AUTOSAR XML (schema 4-2-2)
package /STELLANTIS/EPT/ASWCs
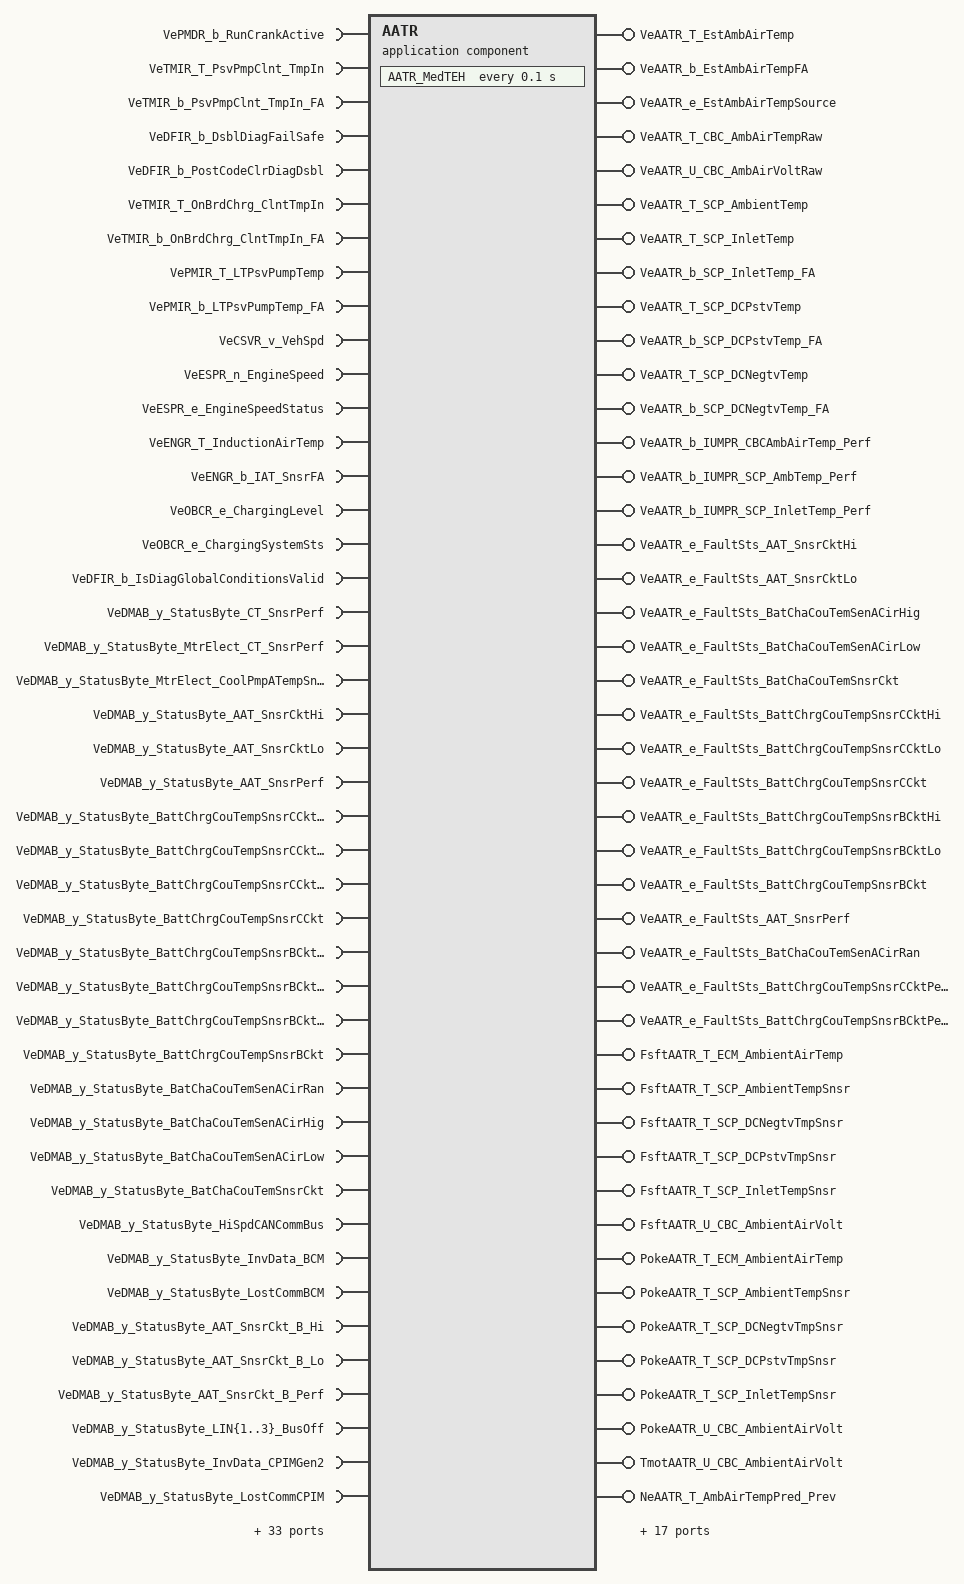
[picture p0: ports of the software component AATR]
  application sw component type AATR
    61 x require port:
      VePMDR_b_RunCrankActive: variation-point={short-label=vpVePMDR_b_RunCrankActive, sw-syscond=1}, nonqueued-receiver-com-spec{data-element=Value, init-value=0}, required-interface=VePMDR_b_RunCrankActive
      VeTMIR_T_PsvPmpClnt_TmpIn: variation-point={short-label=vpVeTMIR_T_PsvPmpClnt_TmpIn, sw-syscond=1}, nonqueued-receiver-com-spec{data-element=Value, init-value=0}, required-interface=VeTMIR_T_PsvPmpClnt_TmpIn
      VeTMIR_b_PsvPmpClnt_TmpIn_FA: variation-point={short-label=vpVeTMIR_b_PsvPmpClnt_TmpIn_FA, sw-syscond=1}, nonqueued-receiver-com-spec{data-element=Value, init-value=0}, required-interface=VeTMIR_b_PsvPmpClnt_TmpIn_FA
      VeDFIR_b_DsblDiagFailSafe: variation-point={short-label=vpVeDFIR_b_DsblDiagFailSafe, sw-syscond=1}, nonqueued-receiver-com-spec{data-element=Value, init-value=0}, required-interface=VeDFIR_b_DsblDiagFailSafe
      VeDFIR_b_PostCodeClrDiagDsbl: variation-point={short-label=vpVeDFIR_b_PostCodeClrDiagDsbl, sw-syscond=1}, nonqueued-receiver-com-spec{data-element=Value, init-value=0}, required-interface=VeDFIR_b_PostCodeClrDiagDsbl
      VeTMIR_T_OnBrdChrg_ClntTmpIn: variation-point={short-label=vpVeTMIR_T_OnBrdChrg_ClntTmpIn, sw-syscond=1}, nonqueued-receiver-com-spec{data-element=Value, init-value=0}, required-interface=VeTMIR_T_OnBrdChrg_ClntTmpIn
      VeTMIR_b_OnBrdChrg_ClntTmpIn_FA: variation-point={short-label=vpVeTMIR_b_OnBrdChrg_ClntTmpIn_FA, sw-syscond=1}, nonqueued-receiver-com-spec{data-element=Value, init-value=0}, required-interface=VeTMIR_b_OnBrdChrg_ClntTmpIn_FA
      VePMIR_T_LTPsvPumpTemp: variation-point={short-label=vpVePMIR_T_LTPsvPumpTemp, sw-syscond=1}, nonqueued-receiver-com-spec{data-element=Value, init-value=0}, required-interface=VePMIR_T_LTPsvPumpTemp
      VePMIR_b_LTPsvPumpTemp_FA: variation-point={short-label=vpVePMIR_b_LTPsvPumpTemp_FA, sw-syscond=1}, nonqueued-receiver-com-spec{data-element=Value, init-value=0}, required-interface=VePMIR_b_LTPsvPumpTemp_FA
      VeCSVR_v_VehSpd: variation-point={short-label=vpVeCSVR_v_VehSpd, sw-syscond=1}, nonqueued-receiver-com-spec{data-element=Value, init-value=0}, required-interface=VeCSVR_v_VehSpd
      VeESPR_n_EngineSpeed: variation-point={short-label=vpVeESPR_n_EngineSpeed, sw-syscond=1}, nonqueued-receiver-com-spec{data-element=Value, init-value=0}, required-interface=VeESPR_n_EngineSpeed
      VeESPR_e_EngineSpeedStatus: variation-point={short-label=vpVeESPR_e_EngineSpeedStatus, sw-syscond=1}, nonqueued-receiver-com-spec{data-element=Value, init-value=CeESPR_e_EngSpdNormal}, required-interface=VeESPR_e_EngineSpeedStatus
      VeENGR_T_InductionAirTemp: variation-point={short-label=vpVeENGR_T_InductionAirTemp, sw-syscond=1}, nonqueued-receiver-com-spec{data-element=Value, init-value=0}, required-interface=VeENGR_T_InductionAirTemp
      VeENGR_b_IAT_SnsrFA: variation-point={short-label=vpVeENGR_b_IAT_SnsrFA, sw-syscond=1}, nonqueued-receiver-com-spec{data-element=Value, init-value=0}, required-interface=VeENGR_b_IAT_SnsrFA
      VeOBCR_e_ChargingLevel: variation-point={short-label=vpVeOBCR_e_ChargingLevel, sw-syscond=1}, nonqueued-receiver-com-spec{data-element=Value, init-value=CeOBCR_e_ChargingLvlDefault}, required-interface=VeOBCR_e_ChargingLevel
      VeOBCR_e_ChargingSystemSts: variation-point={short-label=vpVeOBCR_e_ChargingSystemSts, sw-syscond=1}, nonqueued-receiver-com-spec{data-element=Value, init-value=CeOBCR_e_NotCharging}, required-interface=VeOBCR_e_ChargingSystemSts
      VeDFIR_b_IsDiagGlobalConditionsValid: variation-point={short-label=vpVeDFIR_b_IsDiagGlobalConditionsValid, sw-syscond=1}, nonqueued-receiver-com-spec{data-element=Value, init-value=0}, required-interface=VeDFIR_b_IsDiagGlobalConditionsValid
      VeDMAB_y_StatusByte_CT_SnsrPerf: nonqueued-receiver-com-spec{data-element=Value, init-value=0}, required-interface=VeDMAB_y_StatusByte_CT_SnsrPerf
      VeDMAB_y_StatusByte_MtrElect_CT_SnsrPerf: nonqueued-receiver-com-spec{data-element=Value, init-value=0}, required-interface=VeDMAB_y_StatusByte_MtrElect_CT_SnsrPerf
      VeDMAB_y_StatusByte_MtrElect_CoolPmpATempSnsrPerf: nonqueued-receiver-com-spec{data-element=Value, init-value=0}, required-interface=VeDMAB_y_StatusByte_MtrElect_CoolPmpATempSnsrPerf
      VeDMAB_y_StatusByte_AAT_SnsrCktHi: nonqueued-receiver-com-spec{data-element=Value, init-value=0}, required-interface=VeDMAB_y_StatusByte_AAT_SnsrCktHi
      VeDMAB_y_StatusByte_AAT_SnsrCktLo: nonqueued-receiver-com-spec{data-element=Value, init-value=0}, required-interface=VeDMAB_y_StatusByte_AAT_SnsrCktLo
      VeDMAB_y_StatusByte_AAT_SnsrPerf: nonqueued-receiver-com-spec{data-element=Value, init-value=0}, required-interface=VeDMAB_y_StatusByte_AAT_SnsrPerf
      VeDMAB_y_StatusByte_BattChrgCouTempSnsrCCktPerf: nonqueued-receiver-com-spec{data-element=Value, init-value=0}, required-interface=VeDMAB_y_StatusByte_BattChrgCouTempSnsrCCktPerf
      VeDMAB_y_StatusByte_BattChrgCouTempSnsrCCktHi: nonqueued-receiver-com-spec{data-element=Value, init-value=0}, required-interface=VeDMAB_y_StatusByte_BattChrgCouTempSnsrCCktHi
      VeDMAB_y_StatusByte_BattChrgCouTempSnsrCCktLo: nonqueued-receiver-com-spec{data-element=Value, init-value=0}, required-interface=VeDMAB_y_StatusByte_BattChrgCouTempSnsrCCktLo
      VeDMAB_y_StatusByte_BattChrgCouTempSnsrCCkt: nonqueued-receiver-com-spec{data-element=Value, init-value=0}, required-interface=VeDMAB_y_StatusByte_BattChrgCouTempSnsrCCkt
      VeDMAB_y_StatusByte_BattChrgCouTempSnsrBCktPerf: nonqueued-receiver-com-spec{data-element=Value, init-value=0}, required-interface=VeDMAB_y_StatusByte_BattChrgCouTempSnsrBCktPerf
      VeDMAB_y_StatusByte_BattChrgCouTempSnsrBCktHi: nonqueued-receiver-com-spec{data-element=Value, init-value=0}, required-interface=VeDMAB_y_StatusByte_BattChrgCouTempSnsrBCktHi
      VeDMAB_y_StatusByte_BattChrgCouTempSnsrBCktLo: nonqueued-receiver-com-spec{data-element=Value, init-value=0}, required-interface=VeDMAB_y_StatusByte_BattChrgCouTempSnsrBCktLo
      VeDMAB_y_StatusByte_BattChrgCouTempSnsrBCkt: nonqueued-receiver-com-spec{data-element=Value, init-value=0}, required-interface=VeDMAB_y_StatusByte_BattChrgCouTempSnsrBCkt
      VeDMAB_y_StatusByte_BatChaCouTemSenACirRan: nonqueued-receiver-com-spec{data-element=Value, init-value=0}, required-interface=VeDMAB_y_StatusByte_BatChaCouTemSenACirRan
      VeDMAB_y_StatusByte_BatChaCouTemSenACirHig: nonqueued-receiver-com-spec{data-element=Value, init-value=0}, required-interface=VeDMAB_y_StatusByte_BatChaCouTemSenACirHig
      VeDMAB_y_StatusByte_BatChaCouTemSenACirLow: nonqueued-receiver-com-spec{data-element=Value, init-value=0}, required-interface=VeDMAB_y_StatusByte_BatChaCouTemSenACirLow
      VeDMAB_y_StatusByte_BatChaCouTemSnsrCkt: nonqueued-receiver-com-spec{data-element=Value, init-value=0}, required-interface=VeDMAB_y_StatusByte_BatChaCouTemSnsrCkt
      VeDMAB_y_StatusByte_HiSpdCANCommBus: nonqueued-receiver-com-spec{data-element=Value, init-value=0}, required-interface=VeDMAB_y_StatusByte_HiSpdCANCommBus
      VeDMAB_y_StatusByte_InvData_BCM: nonqueued-receiver-com-spec{data-element=Value, init-value=0}, required-interface=VeDMAB_y_StatusByte_InvData_BCM
      VeDMAB_y_StatusByte_LostCommBCM: nonqueued-receiver-com-spec{data-element=Value, init-value=0}, required-interface=VeDMAB_y_StatusByte_LostCommBCM
      VeDMAB_y_StatusByte_AAT_SnsrCkt_B_Hi: nonqueued-receiver-com-spec{data-element=Value, init-value=0}, required-interface=VeDMAB_y_StatusByte_AAT_SnsrCkt_B_Hi
      VeDMAB_y_StatusByte_AAT_SnsrCkt_B_Lo: nonqueued-receiver-com-spec{data-element=Value, init-value=0}, required-interface=VeDMAB_y_StatusByte_AAT_SnsrCkt_B_Lo
      VeDMAB_y_StatusByte_AAT_SnsrCkt_B_Perf: nonqueued-receiver-com-spec{data-element=Value, init-value=0}, required-interface=VeDMAB_y_StatusByte_AAT_SnsrCkt_B_Perf
      VeDMAB_y_StatusByte_LIN{1..3}_BusOff: nonqueued-receiver-com-spec{data-element=Value, init-value=0}, required-interface=VeDMAB_y_StatusByte_LIN{1..3}_BusOff
      VeDMAB_y_StatusByte_InvData_CPIMGen2: nonqueued-receiver-com-spec{data-element=Value, init-value=0}, required-interface=VeDMAB_y_StatusByte_InvData_CPIMGen2
      VeDMAB_y_StatusByte_LostCommCPIM: nonqueued-receiver-com-spec{data-element=Value, init-value=0}, required-interface=VeDMAB_y_StatusByte_LostCommCPIM
      VeDMAB_y_StatusByte_LostComm_CANC2_BCM: nonqueued-receiver-com-spec{data-element=Value, init-value=0}, required-interface=VeDMAB_y_StatusByte_LostComm_CANC2_BCM
      VeDMAB_y_StatusByte_CommBusOff: nonqueued-receiver-com-spec{data-element=Value, init-value=0}, required-interface=VeDMAB_y_StatusByte_CommBusOff
      VeDMAB_y_StatusByte_LostCommECM_PCM_A: nonqueued-receiver-com-spec{data-element=Value, init-value=0}, required-interface=VeDMAB_y_StatusByte_LostCommECM_PCM_A
      VeDMAB_y_StatusByte_HiSpdFD_CAN3CommBus: nonqueued-receiver-com-spec{data-element=Value, init-value=0}, required-interface=VeDMAB_y_StatusByte_HiSpdFD_CAN3CommBus
      VeDMAB_y_StatusByte_HiSpdFD_CAN3CommBusPerf: nonqueued-receiver-com-spec{data-element=Value, init-value=0}, required-interface=VeDMAB_y_StatusByte_HiSpdFD_CAN3CommBusPerf
      VePLTR_t_HCPOffTime: variation-point={short-label=vpVePLTR_t_HCPOffTime, sw-syscond=1}, nonqueued-receiver-com-spec{data-element=Value, init-value=0}, required-interface=VePLTR_t_HCPOffTime
      VePLTR_b_HCPOffTimeFA: variation-point={short-label=vpVePLTR_b_HCPOffTimeFA, sw-syscond=1}, nonqueued-receiver-com-spec{data-element=Value, init-value=0}, required-interface=VePLTR_b_HCPOffTimeFA
      VeDMAB_y_StatusByte_MtrElect_CT_SnsrCktLo: nonqueued-receiver-com-spec{data-element=Value, init-value=0}, required-interface=VeDMAB_y_StatusByte_MtrElect_CT_SnsrCktLo
      VeDMAB_y_StatusByte_MtrElect_CT_SnsrCktHi: nonqueued-receiver-com-spec{data-element=Value, init-value=0}, required-interface=VeDMAB_y_StatusByte_MtrElect_CT_SnsrCktHi
      VeDMAB_y_StatusByte_CT_SnsrCktLo: nonqueued-receiver-com-spec{data-element=Value, init-value=0}, required-interface=VeDMAB_y_StatusByte_CT_SnsrCktLo
      VeDMAB_y_StatusByte_CT_SnsrCktHi: nonqueued-receiver-com-spec{data-element=Value, init-value=0}, required-interface=VeDMAB_y_StatusByte_CT_SnsrCktHi
      VeDMAB_y_StatusByte_PwrElecPmpPerf: nonqueued-receiver-com-spec{data-element=Value, init-value=0}, required-interface=VeDMAB_y_StatusByte_PwrElecPmpPerf
      VeDMAB_y_StatusByte_MtrElect_CoolPumAOvrSpd: nonqueued-receiver-com-spec{data-element=Value, init-value=0}, required-interface=VeDMAB_y_StatusByte_MtrElect_CoolPumAOvrSpd
      VeDMAB_y_StatusByte_MtrElect_CoolPumBCtrlPerf: nonqueued-receiver-com-spec{data-element=Value, init-value=0}, required-interface=VeDMAB_y_StatusByte_MtrElect_CoolPumBCtrlPerf
      VeDMAB_y_StatusByte_MtrElect_CooPumBOvrSpd: nonqueued-receiver-com-spec{data-element=Value, init-value=0}, required-interface=VeDMAB_y_StatusByte_MtrElect_CooPumBOvrSpd
    43 x provide port:
      VeAATR_T_EstAmbAirTemp: nonqueued-sender-com-spec{data-element=Value, init-value=0}, provided-interface=VeAATR_T_EstAmbAirTemp
      VeAATR_b_EstAmbAirTempFA: nonqueued-sender-com-spec{data-element=Value, init-value=0}, provided-interface=VeAATR_b_EstAmbAirTempFA
      VeAATR_e_EstAmbAirTempSource: nonqueued-sender-com-spec{data-element=Value, init-value=CeAATR_e_AmbAirTemp_Dflt}, provided-interface=VeAATR_e_EstAmbAirTempSource
      VeAATR_T_CBC_AmbAirTempRaw: nonqueued-sender-com-spec{data-element=Value, init-value=0}, provided-interface=VeAATR_T_CBC_AmbAirTempRaw
      VeAATR_U_CBC_AmbAirVoltRaw: nonqueued-sender-com-spec{data-element=Value, init-value=0}, provided-interface=VeAATR_U_CBC_AmbAirVoltRaw
      VeAATR_T_SCP_AmbientTemp: nonqueued-sender-com-spec{data-element=Value, init-value=0}, provided-interface=VeAATR_T_SCP_AmbientTemp
      VeAATR_T_SCP_InletTemp: nonqueued-sender-com-spec{data-element=Value, init-value=0}, provided-interface=VeAATR_T_SCP_InletTemp
      VeAATR_b_SCP_InletTemp_FA: nonqueued-sender-com-spec{data-element=Value, init-value=0}, provided-interface=VeAATR_b_SCP_InletTemp_FA
      VeAATR_T_SCP_DCPstvTemp: nonqueued-sender-com-spec{data-element=Value, init-value=0}, provided-interface=VeAATR_T_SCP_DCPstvTemp
      VeAATR_b_SCP_DCPstvTemp_FA: nonqueued-sender-com-spec{data-element=Value, init-value=0}, provided-interface=VeAATR_b_SCP_DCPstvTemp_FA
      VeAATR_T_SCP_DCNegtvTemp: nonqueued-sender-com-spec{data-element=Value, init-value=0}, provided-interface=VeAATR_T_SCP_DCNegtvTemp
      VeAATR_b_SCP_DCNegtvTemp_FA: nonqueued-sender-com-spec{data-element=Value, init-value=0}, provided-interface=VeAATR_b_SCP_DCNegtvTemp_FA
      VeAATR_b_IUMPR_CBCAmbAirTemp_Perf: variation-point={short-label=vpVeAATR_b_IUMPR_CBCAmbAirTemp_Perf, sw-syscond=1}, nonqueued-sender-com-spec{data-element=Value, init-value=0}, provided-interface=VeAATR_b_IUMPR_CBCAmbAirTemp_Perf
      VeAATR_b_IUMPR_SCP_AmbTemp_Perf: variation-point={short-label=vpVeAATR_b_IUMPR_SCP_AmbTemp_Perf, sw-syscond=1}, nonqueued-sender-com-spec{data-element=Value, init-value=0}, provided-interface=VeAATR_b_IUMPR_SCP_AmbTemp_Perf
      VeAATR_b_IUMPR_SCP_InletTemp_Perf: variation-point={short-label=vpVeAATR_b_IUMPR_SCP_InletTemp_Perf, sw-syscond=1}, nonqueued-sender-com-spec{data-element=Value, init-value=0}, provided-interface=VeAATR_b_IUMPR_SCP_InletTemp_Perf
      VeAATR_e_FaultSts_AAT_SnsrCktHi: nonqueued-sender-com-spec{data-element=Value, init-value=CeDFIB_e_Init}, provided-interface=VeAATR_e_FaultSts_AAT_SnsrCktHi
      VeAATR_e_FaultSts_AAT_SnsrCktLo: nonqueued-sender-com-spec{data-element=Value, init-value=CeDFIB_e_Init}, provided-interface=VeAATR_e_FaultSts_AAT_SnsrCktLo
      VeAATR_e_FaultSts_BatChaCouTemSenACirHig: nonqueued-sender-com-spec{data-element=Value, init-value=CeDFIB_e_Init}, provided-interface=VeAATR_e_FaultSts_BatChaCouTemSenACirHig
      VeAATR_e_FaultSts_BatChaCouTemSenACirLow: nonqueued-sender-com-spec{data-element=Value, init-value=CeDFIB_e_Init}, provided-interface=VeAATR_e_FaultSts_BatChaCouTemSenACirLow
      VeAATR_e_FaultSts_BatChaCouTemSnsrCkt: nonqueued-sender-com-spec{data-element=Value, init-value=CeDFIB_e_Init}, provided-interface=VeAATR_e_FaultSts_BatChaCouTemSnsrCkt
      VeAATR_e_FaultSts_BattChrgCouTempSnsrCCktHi: nonqueued-sender-com-spec{data-element=Value, init-value=CeDFIB_e_Init}, provided-interface=VeAATR_e_FaultSts_BattChrgCouTempSnsrCCktHi
      VeAATR_e_FaultSts_BattChrgCouTempSnsrCCktLo: nonqueued-sender-com-spec{data-element=Value, init-value=CeDFIB_e_Init}, provided-interface=VeAATR_e_FaultSts_BattChrgCouTempSnsrCCktLo
      VeAATR_e_FaultSts_BattChrgCouTempSnsrCCkt: nonqueued-sender-com-spec{data-element=Value, init-value=CeDFIB_e_Init}, provided-interface=VeAATR_e_FaultSts_BattChrgCouTempSnsrCCkt
      VeAATR_e_FaultSts_BattChrgCouTempSnsrBCktHi: nonqueued-sender-com-spec{data-element=Value, init-value=CeDFIB_e_Init}, provided-interface=VeAATR_e_FaultSts_BattChrgCouTempSnsrBCktHi
      VeAATR_e_FaultSts_BattChrgCouTempSnsrBCktLo: nonqueued-sender-com-spec{data-element=Value, init-value=CeDFIB_e_Init}, provided-interface=VeAATR_e_FaultSts_BattChrgCouTempSnsrBCktLo
      VeAATR_e_FaultSts_BattChrgCouTempSnsrBCkt: nonqueued-sender-com-spec{data-element=Value, init-value=CeDFIB_e_Init}, provided-interface=VeAATR_e_FaultSts_BattChrgCouTempSnsrBCkt
      VeAATR_e_FaultSts_AAT_SnsrPerf: nonqueued-sender-com-spec{data-element=Value, init-value=CeDFIB_e_Init}, provided-interface=VeAATR_e_FaultSts_AAT_SnsrPerf
      VeAATR_e_FaultSts_BatChaCouTemSenACirRan: nonqueued-sender-com-spec{data-element=Value, init-value=CeDFIB_e_Init}, provided-interface=VeAATR_e_FaultSts_BatChaCouTemSenACirRan
      VeAATR_e_FaultSts_BattChrgCouTempSnsrCCktPerf: nonqueued-sender-com-spec{data-element=Value, init-value=CeDFIB_e_Init}, provided-interface=VeAATR_e_FaultSts_BattChrgCouTempSnsrCCktPerf
      VeAATR_e_FaultSts_BattChrgCouTempSnsrBCktPerf: nonqueued-sender-com-spec{data-element=Value, init-value=CeDFIB_e_Init}, provided-interface=VeAATR_e_FaultSts_BattChrgCouTempSnsrBCktPerf
      FsftAATR_T_ECM_AmbientAirTemp: server-com-spec=FsftAATR_T_ECM_AmbientAirTemp, provided-interface=FsftAATR_T_ECM_AmbientAirTemp
      FsftAATR_T_SCP_AmbientTempSnsr: server-com-spec=FsftAATR_T_SCP_AmbientTempSnsr, provided-interface=FsftAATR_T_SCP_AmbientTempSnsr
      FsftAATR_T_SCP_DCNegtvTmpSnsr: server-com-spec=FsftAATR_T_SCP_DCNegtvTmpSnsr, provided-interface=FsftAATR_T_SCP_DCNegtvTmpSnsr
      FsftAATR_T_SCP_DCPstvTmpSnsr: server-com-spec=FsftAATR_T_SCP_DCPstvTmpSnsr, provided-interface=FsftAATR_T_SCP_DCPstvTmpSnsr
      FsftAATR_T_SCP_InletTempSnsr: server-com-spec=FsftAATR_T_SCP_InletTempSnsr, provided-interface=FsftAATR_T_SCP_InletTempSnsr
      FsftAATR_U_CBC_AmbientAirVolt: server-com-spec=FsftAATR_U_CBC_AmbientAirVolt, provided-interface=FsftAATR_U_CBC_AmbientAirVolt
      PokeAATR_T_ECM_AmbientAirTemp: server-com-spec{operation=PokeAATR_T_ECM_AmbientAirTemp, queue-length=1}, provided-interface=PokeAATR_T_ECM_AmbientAirTemp
      PokeAATR_T_SCP_AmbientTempSnsr: server-com-spec{operation=PokeAATR_T_SCP_AmbientTempSnsr, queue-length=1}, provided-interface=PokeAATR_T_SCP_AmbientTempSnsr
      PokeAATR_T_SCP_DCNegtvTmpSnsr: server-com-spec{operation=PokeAATR_T_SCP_DCNegtvTmpSnsr, queue-length=1}, provided-interface=PokeAATR_T_SCP_DCNegtvTmpSnsr
      PokeAATR_T_SCP_DCPstvTmpSnsr: server-com-spec{operation=PokeAATR_T_SCP_DCPstvTmpSnsr, queue-length=1}, provided-interface=PokeAATR_T_SCP_DCPstvTmpSnsr
      PokeAATR_T_SCP_InletTempSnsr: server-com-spec{operation=PokeAATR_T_SCP_InletTempSnsr, queue-length=1}, provided-interface=PokeAATR_T_SCP_InletTempSnsr
      PokeAATR_U_CBC_AmbientAirVolt: server-com-spec{operation=PokeAATR_U_CBC_AmbientAirVolt, queue-length=1}, provided-interface=PokeAATR_U_CBC_AmbientAirVolt
      TmotAATR_U_CBC_AmbientAirVolt: server-com-spec=TmotAATR_U_CBC_AmbientAirVolt, provided-interface=TmotAATR_U_CBC_AmbientAirVolt
    18 x require port:
      NeAATR_T_AmbAirTempPred_Prev_Rx: nv-require-com-spec{init-value=0, variable=NeAATR_T_AmbAirTempPred_Prev}, required-interface=NeAATR_T_AmbAirTempPred_Prev
      NeAATR_b_AmbAirTempPred_PrevFA_Rx: nv-require-com-spec{init-value=0, variable=NeAATR_b_AmbAirTempPred_PrevFA}, required-interface=NeAATR_b_AmbAirTempPred_PrevFA
      NeAATR_Cnt_AmbAirTemp_PerfFlt_MFOP_Rx: nv-require-com-spec{init-value=0, variable=NeAATR_Cnt_AmbAirTemp_PerfFlt_MFOP}, required-interface=NeAATR_Cnt_AmbAirTemp_PerfFlt_MFOP
      NeAATR_Cnt_AmbAirVolt_HiFlt_MFOP_Rx: nv-require-com-spec{init-value=0, variable=NeAATR_Cnt_AmbAirVolt_HiFlt_MFOP}, required-interface=NeAATR_Cnt_AmbAirVolt_HiFlt_MFOP
      NeAATR_Cnt_AmbAirVolt_LoFlt_MFOP_Rx: nv-require-com-spec{init-value=0, variable=NeAATR_Cnt_AmbAirVolt_LoFlt_MFOP}, required-interface=NeAATR_Cnt_AmbAirVolt_LoFlt_MFOP
      NeAATR_Cnt_DCPstvTemp_HiFlt_MFOP_Rx: nv-require-com-spec{init-value=0, variable=NeAATR_Cnt_DCPstvTemp_HiFlt_MFOP}, required-interface=NeAATR_Cnt_DCPstvTemp_HiFlt_MFOP
      NeAATR_Cnt_ECM_IntakeTemp_PerfFlt_MFOP_Rx: nv-require-com-spec{init-value=0, variable=NeAATR_Cnt_ECM_IntakeTemp_PerfFlt_MFOP}, required-interface=NeAATR_Cnt_ECM_IntakeTemp_PerfFlt_MFOP
      NeAATR_Cnt_SCP_DCNegtvTemp_Flt_MFOP_Rx: nv-require-com-spec{init-value=0, variable=NeAATR_Cnt_SCP_DCNegtvTemp_Flt_MFOP}, required-interface=NeAATR_Cnt_SCP_DCNegtvTemp_Flt_MFOP
      NeAATR_Cnt_SCP_DCNegtvTemp_HiFlt_MFOP_Rx: nv-require-com-spec{init-value=0, variable=NeAATR_Cnt_SCP_DCNegtvTemp_HiFlt_MFOP}, required-interface=NeAATR_Cnt_SCP_DCNegtvTemp_HiFlt_MFOP
      NeAATR_Cnt_SCP_DCNegtvTemp_LoFlt_MFOP_Rx: nv-require-com-spec{init-value=0, variable=NeAATR_Cnt_SCP_DCNegtvTemp_LoFlt_MFOP}, required-interface=NeAATR_Cnt_SCP_DCNegtvTemp_LoFlt_MFOP
      NeAATR_Cnt_SCP_DCNegtvTemp_PerfFlt_MFOP_Rx: nv-require-com-spec{init-value=0, variable=NeAATR_Cnt_SCP_DCNegtvTemp_PerfFlt_MFOP}, required-interface=NeAATR_Cnt_SCP_DCNegtvTemp_PerfFlt_MFOP
      NeAATR_Cnt_SCP_DCPstvTemp_Flt_MFOP_Rx: nv-require-com-spec{init-value=0, variable=NeAATR_Cnt_SCP_DCPstvTemp_Flt_MFOP}, required-interface=NeAATR_Cnt_SCP_DCPstvTemp_Flt_MFOP
      NeAATR_Cnt_SCP_DCPstvTemp_LoFlt_MFOP_Rx: nv-require-com-spec{init-value=0, variable=NeAATR_Cnt_SCP_DCPstvTemp_LoFlt_MFOP}, required-interface=NeAATR_Cnt_SCP_DCPstvTemp_LoFlt_MFOP
      NeAATR_Cnt_SCP_DCPstvTemp_PerfFlt_MFOP_Rx: nv-require-com-spec{init-value=0, variable=NeAATR_Cnt_SCP_DCPstvTemp_PerfFlt_MFOP}, required-interface=NeAATR_Cnt_SCP_DCPstvTemp_PerfFlt_MFOP
      NeAATR_Cnt_SCP_InletTemp_Flt_MFOP_Rx: nv-require-com-spec{init-value=0, variable=NeAATR_Cnt_SCP_InletTemp_Flt_MFOP}, required-interface=NeAATR_Cnt_SCP_InletTemp_Flt_MFOP
      NeAATR_Cnt_SCP_InletTemp_HiFlt_MFOP_Rx: nv-require-com-spec{init-value=0, variable=NeAATR_Cnt_SCP_InletTemp_HiFlt_MFOP}, required-interface=NeAATR_Cnt_SCP_InletTemp_HiFlt_MFOP
      NeAATR_Cnt_SCP_InletTemp_LoFlt_MFOP_Rx: nv-require-com-spec{init-value=0, variable=NeAATR_Cnt_SCP_InletTemp_LoFlt_MFOP}, required-interface=NeAATR_Cnt_SCP_InletTemp_LoFlt_MFOP
      NeAATR_Cnt_SCP_InletTemp_PerfFlt_MFOP_Rx: nv-require-com-spec{init-value=0, variable=NeAATR_Cnt_SCP_InletTemp_PerfFlt_MFOP}, required-interface=NeAATR_Cnt_SCP_InletTemp_PerfFlt_MFOP
    18 x provide port:
      NeAATR_T_AmbAirTempPred_Prev: nv-provide-com-spec{ram-block-init-value=0, variable=NeAATR_T_AmbAirTempPred_Prev}, provided-interface=NeAATR_T_AmbAirTempPred_Prev
      NeAATR_b_AmbAirTempPred_PrevFA: nv-provide-com-spec{ram-block-init-value=0, variable=NeAATR_b_AmbAirTempPred_PrevFA}, provided-interface=NeAATR_b_AmbAirTempPred_PrevFA
      NeAATR_Cnt_AmbAirTemp_PerfFlt_MFOP: nv-provide-com-spec{ram-block-init-value=0, variable=NeAATR_Cnt_AmbAirTemp_PerfFlt_MFOP}, provided-interface=NeAATR_Cnt_AmbAirTemp_PerfFlt_MFOP
      NeAATR_Cnt_AmbAirVolt_HiFlt_MFOP: nv-provide-com-spec{ram-block-init-value=0, variable=NeAATR_Cnt_AmbAirVolt_HiFlt_MFOP}, provided-interface=NeAATR_Cnt_AmbAirVolt_HiFlt_MFOP
      NeAATR_Cnt_AmbAirVolt_LoFlt_MFOP: nv-provide-com-spec{ram-block-init-value=0, variable=NeAATR_Cnt_AmbAirVolt_LoFlt_MFOP}, provided-interface=NeAATR_Cnt_AmbAirVolt_LoFlt_MFOP
      NeAATR_Cnt_DCPstvTemp_HiFlt_MFOP: nv-provide-com-spec{ram-block-init-value=0, variable=NeAATR_Cnt_DCPstvTemp_HiFlt_MFOP}, provided-interface=NeAATR_Cnt_DCPstvTemp_HiFlt_MFOP
      NeAATR_Cnt_ECM_IntakeTemp_PerfFlt_MFOP: nv-provide-com-spec{ram-block-init-value=0, variable=NeAATR_Cnt_ECM_IntakeTemp_PerfFlt_MFOP}, provided-interface=NeAATR_Cnt_ECM_IntakeTemp_PerfFlt_MFOP
      NeAATR_Cnt_SCP_DCNegtvTemp_Flt_MFOP: nv-provide-com-spec{ram-block-init-value=0, variable=NeAATR_Cnt_SCP_DCNegtvTemp_Flt_MFOP}, provided-interface=NeAATR_Cnt_SCP_DCNegtvTemp_Flt_MFOP
      NeAATR_Cnt_SCP_DCNegtvTemp_HiFlt_MFOP: nv-provide-com-spec{ram-block-init-value=0, variable=NeAATR_Cnt_SCP_DCNegtvTemp_HiFlt_MFOP}, provided-interface=NeAATR_Cnt_SCP_DCNegtvTemp_HiFlt_MFOP
      NeAATR_Cnt_SCP_DCNegtvTemp_LoFlt_MFOP: nv-provide-com-spec{ram-block-init-value=0, variable=NeAATR_Cnt_SCP_DCNegtvTemp_LoFlt_MFOP}, provided-interface=NeAATR_Cnt_SCP_DCNegtvTemp_LoFlt_MFOP
      NeAATR_Cnt_SCP_DCNegtvTemp_PerfFlt_MFOP: nv-provide-com-spec{ram-block-init-value=0, variable=NeAATR_Cnt_SCP_DCNegtvTemp_PerfFlt_MFOP}, provided-interface=NeAATR_Cnt_SCP_DCNegtvTemp_PerfFlt_MFOP
      NeAATR_Cnt_SCP_DCPstvTemp_Flt_MFOP: nv-provide-com-spec{ram-block-init-value=0, variable=NeAATR_Cnt_SCP_DCPstvTemp_Flt_MFOP}, provided-interface=NeAATR_Cnt_SCP_DCPstvTemp_Flt_MFOP
      NeAATR_Cnt_SCP_DCPstvTemp_LoFlt_MFOP: nv-provide-com-spec{ram-block-init-value=0, variable=NeAATR_Cnt_SCP_DCPstvTemp_LoFlt_MFOP}, provided-interface=NeAATR_Cnt_SCP_DCPstvTemp_LoFlt_MFOP
      NeAATR_Cnt_SCP_DCPstvTemp_PerfFlt_MFOP: nv-provide-com-spec{ram-block-init-value=0, variable=NeAATR_Cnt_SCP_DCPstvTemp_PerfFlt_MFOP}, provided-interface=NeAATR_Cnt_SCP_DCPstvTemp_PerfFlt_MFOP
      NeAATR_Cnt_SCP_InletTemp_Flt_MFOP: nv-provide-com-spec{ram-block-init-value=0, variable=NeAATR_Cnt_SCP_InletTemp_Flt_MFOP}, provided-interface=NeAATR_Cnt_SCP_InletTemp_Flt_MFOP
      NeAATR_Cnt_SCP_InletTemp_HiFlt_MFOP: nv-provide-com-spec{ram-block-init-value=0, variable=NeAATR_Cnt_SCP_InletTemp_HiFlt_MFOP}, provided-interface=NeAATR_Cnt_SCP_InletTemp_HiFlt_MFOP
      NeAATR_Cnt_SCP_InletTemp_LoFlt_MFOP: nv-provide-com-spec{ram-block-init-value=0, variable=NeAATR_Cnt_SCP_InletTemp_LoFlt_MFOP}, provided-interface=NeAATR_Cnt_SCP_InletTemp_LoFlt_MFOP
      NeAATR_Cnt_SCP_InletTemp_PerfFlt_MFOP: nv-provide-com-spec{ram-block-init-value=0, variable=NeAATR_Cnt_SCP_InletTemp_PerfFlt_MFOP}, provided-interface=NeAATR_Cnt_SCP_InletTemp_PerfFlt_MFOP
    behavior IB_AATR: data-type-mapping=msADTtoIDTMapping, handle-termination-and-restart=NO-SUPPORT, included-data-type-set=data-type=TeAATR_e_PlgInTimer_CalSet
      timing event Event_MedTEH: start-on-event=AATR_MedTEH, period=0.1
      13 x operation invoked event:
        Event_FsftAATR_T_ECM_AmbientAirTemp: start-on-event=FsftAATR_T_ECM_AmbientAirTemp, operation=FsftAATR_T_ECM_AmbientAirTemp.FsftAATR_T_ECM_AmbientAirTemp
        Event_FsftAATR_T_SCP_AmbientTempSnsr: start-on-event=FsftAATR_T_SCP_AmbientTempSnsr, operation=FsftAATR_T_SCP_AmbientTempSnsr.FsftAATR_T_SCP_AmbientTempSnsr
        Event_FsftAATR_T_SCP_DCNegtvTmpSnsr: start-on-event=FsftAATR_T_SCP_DCNegtvTmpSnsr, operation=FsftAATR_T_SCP_DCNegtvTmpSnsr.FsftAATR_T_SCP_DCNegtvTmpSnsr
        Event_FsftAATR_T_SCP_DCPstvTmpSnsr: start-on-event=FsftAATR_T_SCP_DCPstvTmpSnsr, operation=FsftAATR_T_SCP_DCPstvTmpSnsr.FsftAATR_T_SCP_DCPstvTmpSnsr
        Event_FsftAATR_T_SCP_InletTempSnsr: start-on-event=FsftAATR_T_SCP_InletTempSnsr, operation=FsftAATR_T_SCP_InletTempSnsr.FsftAATR_T_SCP_InletTempSnsr
        Event_FsftAATR_U_CBC_AmbientAirVolt: start-on-event=FsftAATR_U_CBC_AmbientAirVolt, operation=FsftAATR_U_CBC_AmbientAirVolt.FsftAATR_U_CBC_AmbientAirVolt
        Event_PokeAATR_T_ECM_AmbientAirTemp: start-on-event=PokeAATR_T_ECM_AmbientAirTemp, operation=PokeAATR_T_ECM_AmbientAirTemp.PokeAATR_T_ECM_AmbientAirTemp
        Event_PokeAATR_T_SCP_AmbientTempSnsr: start-on-event=PokeAATR_T_SCP_AmbientTempSnsr, operation=PokeAATR_T_SCP_AmbientTempSnsr.PokeAATR_T_SCP_AmbientTempSnsr
        Event_PokeAATR_T_SCP_DCNegtvTmpSnsr: start-on-event=PokeAATR_T_SCP_DCNegtvTmpSnsr, operation=PokeAATR_T_SCP_DCNegtvTmpSnsr.PokeAATR_T_SCP_DCNegtvTmpSnsr
        Event_PokeAATR_T_SCP_DCPstvTmpSnsr: start-on-event=PokeAATR_T_SCP_DCPstvTmpSnsr, operation=PokeAATR_T_SCP_DCPstvTmpSnsr.PokeAATR_T_SCP_DCPstvTmpSnsr
        Event_PokeAATR_T_SCP_InletTempSnsr: start-on-event=PokeAATR_T_SCP_InletTempSnsr, operation=PokeAATR_T_SCP_InletTempSnsr.PokeAATR_T_SCP_InletTempSnsr
        Event_PokeAATR_U_CBC_AmbientAirVolt: start-on-event=PokeAATR_U_CBC_AmbientAirVolt, operation=PokeAATR_U_CBC_AmbientAirVolt.PokeAATR_U_CBC_AmbientAirVolt
        Event_TmotAATR_U_CBC_AmbientAirVolt: start-on-event=TmotAATR_U_CBC_AmbientAirVolt, operation=TmotAATR_U_CBC_AmbientAirVolt.TmotAATR_U_CBC_AmbientAirVolt
      init event Event_AATR_ac_Init: start-on-event=AATR_ac_Init
      init event Event_PwrOn: start-on-event=AATR_PwrOn
      init event Event_PwrOff: start-on-event=AATR_PwrOff
      explicit-inter-runnable-variables:
        18 x data, all with category=VALUE, sw-calibration-access=READ-ONLY:
          ECM_AmbAirTemp_Init_write_IRV: type=Float, init-value=0
          ECM_AmbAirTemp_InitFA_write_IRV: type=Boolean, init-value=0
          CBC_AmbAirTemp_Init_write_IRV: type=Float, init-value=0
          CBC_AmbAirTemp_InitFA_write_IRV: type=Boolean, init-value=0
          CBC_AmbAirTempSrc_Init_write_IRV: type=TeAATR_e_CBC_AmbientAirVoltSrc, init-value=CeAATR_e_CBC_AmbVoltSrc_Dflt
          SCP_AmbientTemp_Init_write_IRV: type=Float, init-value=0, variation-point={short-label=vpSCP_AmbientTemp_Init_write_IRV, sw-syscond=1}
          SCP_AmbientTempFA_Init_write_IRV: type=Boolean, init-value=0, variation-point={short-label=vpSCP_AmbientTempFA_Init_write_IRV, sw-syscond=1}
          SCP_InletTempSnsr_Init_write_IRV: type=Float, init-value=0, variation-point={short-label=vpSCP_InletTempSnsr_Init_write_IRV, sw-syscond=1}
          SCP_InletTempSnsrFA_Init_write_IRV: type=Boolean, init-value=0, variation-point={short-label=vpSCP_InletTempSnsrFA_Init_write_IRV, sw-syscond=1}
          SCP_DCPstvTemp_Init_write_IRV: type=Float, init-value=0, variation-point={short-label=vpSCP_DCPstvTemp_Init_write_IRV, sw-syscond=1}
          SCP_DCPstvTempFA_Init_write_IRV: type=Boolean, init-value=0, variation-point={short-label=vpSCP_DCPstvTempFA_Init_write_IRV, sw-syscond=1}
          SCP_DCNegtvTemp_Init_write_IRV: type=Float, init-value=0, variation-point={short-label=vpSCP_DCNegtvTemp_Init_write_IRV, sw-syscond=1}
          SCP_DCNegtvTempFA_Init_write_IRV: type=Boolean, init-value=0, variation-point={short-label=vpSCP_DCNegtvTempFA_Init_write_IRV, sw-syscond=1}
          SCP_InletTempSnsrSNA_Init_write_IRV: type=Boolean, init-value=0, variation-point={short-label=vpSCP_InletTempSnsrSNA_Init_write_IRV, sw-syscond=1}
          SCP_DCPstvTempSNA_Init_write_IRV: type=Boolean, init-value=0, variation-point={short-label=vpSCP_DCPstvTempSNA_Init_write_IRV, sw-syscond=1}
          SCP_DCNegtvTempSNA_Init_write_IRV: type=Boolean, init-value=0, variation-point={short-label=vpSCP_DCNegtvTempSNA_Init_write_IRV, sw-syscond=1}
          AmbAirTemp_Saved_write_IRV: type=Float, init-value=0, variation-point={short-label=vpAmbAirTemp_Saved_write_IRV, sw-syscond=1}
          AmbAirTempFA_Saved_write_IRV: type=Boolean, init-value=0, variation-point={short-label=vpAmbAirTempFA_Saved_write_IRV, sw-syscond=1}
      17 x runnable:
        AATR_ac_Init
          data-send-points:
            16 x access:
              OUT_VeAATR_e_EstAmbAirTempSource_Value: accessed-variable=VeAATR_e_EstAmbAirTempSource.Value
              OUT_VeAATR_e_FaultSts_AAT_SnsrCktHi_Value: accessed-variable=VeAATR_e_FaultSts_AAT_SnsrCktHi.Value
              OUT_VeAATR_e_FaultSts_AAT_SnsrCktLo_Value: accessed-variable=VeAATR_e_FaultSts_AAT_SnsrCktLo.Value
              OUT_VeAATR_e_FaultSts_BatChaCouTemSenACirHig_Value: accessed-variable=VeAATR_e_FaultSts_BatChaCouTemSenACirHig.Value
              OUT_VeAATR_e_FaultSts_BatChaCouTemSenACirLow_Value: accessed-variable=VeAATR_e_FaultSts_BatChaCouTemSenACirLow.Value
              OUT_VeAATR_e_FaultSts_BatChaCouTemSnsrCkt_Value: accessed-variable=VeAATR_e_FaultSts_BatChaCouTemSnsrCkt.Value
              OUT_VeAATR_e_FaultSts_BattChrgCouTempSnsrCCktHi_Value: accessed-variable=VeAATR_e_FaultSts_BattChrgCouTempSnsrCCktHi.Value
              OUT_VeAATR_e_FaultSts_BattChrgCouTempSnsrCCktLo_Value: accessed-variable=VeAATR_e_FaultSts_BattChrgCouTempSnsrCCktLo.Value
              OUT_VeAATR_e_FaultSts_BattChrgCouTempSnsrCCkt_Value: accessed-variable=VeAATR_e_FaultSts_BattChrgCouTempSnsrCCkt.Value
              OUT_VeAATR_e_FaultSts_BattChrgCouTempSnsrBCktHi_Value: accessed-variable=VeAATR_e_FaultSts_BattChrgCouTempSnsrBCktHi.Value
              OUT_VeAATR_e_FaultSts_BattChrgCouTempSnsrBCktLo_Value: accessed-variable=VeAATR_e_FaultSts_BattChrgCouTempSnsrBCktLo.Value
              OUT_VeAATR_e_FaultSts_BattChrgCouTempSnsrBCkt_Value: accessed-variable=VeAATR_e_FaultSts_BattChrgCouTempSnsrBCkt.Value
              OUT_VeAATR_e_FaultSts_AAT_SnsrPerf_Value: accessed-variable=VeAATR_e_FaultSts_AAT_SnsrPerf.Value
              OUT_VeAATR_e_FaultSts_BatChaCouTemSenACirRan_Value: accessed-variable=VeAATR_e_FaultSts_BatChaCouTemSenACirRan.Value
              OUT_VeAATR_e_FaultSts_BattChrgCouTempSnsrCCktPerf_Value: accessed-variable=VeAATR_e_FaultSts_BattChrgCouTempSnsrCCktPerf.Value
              OUT_VeAATR_e_FaultSts_BattChrgCouTempSnsrBCktPerf_Value: accessed-variable=VeAATR_e_FaultSts_BattChrgCouTempSnsrBCktPerf.Value
          written-local-variables:
            access WV_AmbAirTempFA_Saved_write_IRV: accessed-variable=AmbAirTempFA_Saved_write_IRV, variation-point={short-label=vpWV_AmbAirTempFA_Saved_write_IRV, sw-syscond=1}
            access WV_AmbAirTemp_Saved_write_IRV: accessed-variable=AmbAirTemp_Saved_write_IRV, variation-point={short-label=vpWV_AmbAirTemp_Saved_write_IRV, sw-syscond=1}
        AATR_PwrOn
          data-receive-point-by-arguments:
            18 x access:
              IN_NeAATR_Cnt_AmbAirTemp_PerfFlt_MFOP_Rx_NeAATR_Cnt_AmbAirTemp_PerfFlt_MFOP: accessed-variable=NeAATR_Cnt_AmbAirTemp_PerfFlt_MFOP_Rx.NeAATR_Cnt_AmbAirTemp_PerfFlt_MFOP
              IN_NeAATR_Cnt_AmbAirVolt_HiFlt_MFOP_Rx_NeAATR_Cnt_AmbAirVolt_HiFlt_MFOP: accessed-variable=NeAATR_Cnt_AmbAirVolt_HiFlt_MFOP_Rx.NeAATR_Cnt_AmbAirVolt_HiFlt_MFOP
              IN_NeAATR_Cnt_AmbAirVolt_LoFlt_MFOP_Rx_NeAATR_Cnt_AmbAirVolt_LoFlt_MFOP: accessed-variable=NeAATR_Cnt_AmbAirVolt_LoFlt_MFOP_Rx.NeAATR_Cnt_AmbAirVolt_LoFlt_MFOP
              IN_NeAATR_Cnt_DCPstvTemp_HiFlt_MFOP_Rx_NeAATR_Cnt_DCPstvTemp_HiFlt_MFOP: accessed-variable=NeAATR_Cnt_DCPstvTemp_HiFlt_MFOP_Rx.NeAATR_Cnt_DCPstvTemp_HiFlt_MFOP
              IN_NeAATR_Cnt_ECM_IntakeTemp_PerfFlt_MFOP_Rx_NeAATR_Cnt_ECM_IntakeTemp_PerfFlt_MFOP: accessed-variable=NeAATR_Cnt_ECM_IntakeTemp_PerfFlt_MFOP_Rx.NeAATR_Cnt_ECM_IntakeTemp_PerfFlt_MFOP
              IN_NeAATR_Cnt_SCP_DCNegtvTemp_Flt_MFOP_Rx_NeAATR_Cnt_SCP_DCNegtvTemp_Flt_MFOP: accessed-variable=NeAATR_Cnt_SCP_DCNegtvTemp_Flt_MFOP_Rx.NeAATR_Cnt_SCP_DCNegtvTemp_Flt_MFOP
              IN_NeAATR_Cnt_SCP_DCNegtvTemp_HiFlt_MFOP_Rx_NeAATR_Cnt_SCP_DCNegtvTemp_HiFlt_MFOP: accessed-variable=NeAATR_Cnt_SCP_DCNegtvTemp_HiFlt_MFOP_Rx.NeAATR_Cnt_SCP_DCNegtvTemp_HiFlt_MFOP
              IN_NeAATR_Cnt_SCP_DCNegtvTemp_LoFlt_MFOP_Rx_NeAATR_Cnt_SCP_DCNegtvTemp_LoFlt_MFOP: accessed-variable=NeAATR_Cnt_SCP_DCNegtvTemp_LoFlt_MFOP_Rx.NeAATR_Cnt_SCP_DCNegtvTemp_LoFlt_MFOP
              IN_NeAATR_Cnt_SCP_DCNegtvTemp_PerfFlt_MFOP_Rx_NeAATR_Cnt_SCP_DCNegtvTemp_PerfFlt_MFOP: accessed-variable=NeAATR_Cnt_SCP_DCNegtvTemp_PerfFlt_MFOP_Rx.NeAATR_Cnt_SCP_DCNegtvTemp_PerfFlt_MFOP
              IN_NeAATR_Cnt_SCP_DCPstvTemp_Flt_MFOP_Rx_NeAATR_Cnt_SCP_DCPstvTemp_Flt_MFOP: accessed-variable=NeAATR_Cnt_SCP_DCPstvTemp_Flt_MFOP_Rx.NeAATR_Cnt_SCP_DCPstvTemp_Flt_MFOP
              IN_NeAATR_Cnt_SCP_DCPstvTemp_LoFlt_MFOP_Rx_NeAATR_Cnt_SCP_DCPstvTemp_LoFlt_MFOP: accessed-variable=NeAATR_Cnt_SCP_DCPstvTemp_LoFlt_MFOP_Rx.NeAATR_Cnt_SCP_DCPstvTemp_LoFlt_MFOP
              IN_NeAATR_Cnt_SCP_DCPstvTemp_PerfFlt_MFOP_Rx_NeAATR_Cnt_SCP_DCPstvTemp_PerfFlt_MFOP: accessed-variable=NeAATR_Cnt_SCP_DCPstvTemp_PerfFlt_MFOP_Rx.NeAATR_Cnt_SCP_DCPstvTemp_PerfFlt_MFOP
              IN_NeAATR_Cnt_SCP_InletTemp_Flt_MFOP_Rx_NeAATR_Cnt_SCP_InletTemp_Flt_MFOP: accessed-variable=NeAATR_Cnt_SCP_InletTemp_Flt_MFOP_Rx.NeAATR_Cnt_SCP_InletTemp_Flt_MFOP
              IN_NeAATR_Cnt_SCP_InletTemp_HiFlt_MFOP_Rx_NeAATR_Cnt_SCP_InletTemp_HiFlt_MFOP: accessed-variable=NeAATR_Cnt_SCP_InletTemp_HiFlt_MFOP_Rx.NeAATR_Cnt_SCP_InletTemp_HiFlt_MFOP
              IN_NeAATR_Cnt_SCP_InletTemp_LoFlt_MFOP_Rx_NeAATR_Cnt_SCP_InletTemp_LoFlt_MFOP: accessed-variable=NeAATR_Cnt_SCP_InletTemp_LoFlt_MFOP_Rx.NeAATR_Cnt_SCP_InletTemp_LoFlt_MFOP
              IN_NeAATR_Cnt_SCP_InletTemp_PerfFlt_MFOP_Rx_NeAATR_Cnt_SCP_InletTemp_PerfFlt_MFOP: accessed-variable=NeAATR_Cnt_SCP_InletTemp_PerfFlt_MFOP_Rx.NeAATR_Cnt_SCP_InletTemp_PerfFlt_MFOP
              IN_NeAATR_T_AmbAirTempPred_Prev_Rx_NeAATR_T_AmbAirTempPred_Prev: accessed-variable=NeAATR_T_AmbAirTempPred_Prev_Rx.NeAATR_T_AmbAirTempPred_Prev
              IN_NeAATR_b_AmbAirTempPred_PrevFA_Rx_NeAATR_b_AmbAirTempPred_PrevFA: accessed-variable=NeAATR_b_AmbAirTempPred_PrevFA_Rx.NeAATR_b_AmbAirTempPred_PrevFA
          data-send-points:
            30 x access:
              OUT_VeAATR_T_EstAmbAirTemp_Value: accessed-variable=VeAATR_T_EstAmbAirTemp.Value
              OUT_VeAATR_b_EstAmbAirTempFA_Value: accessed-variable=VeAATR_b_EstAmbAirTempFA.Value
              OUT_VeAATR_b_SCP_InletTemp_FA_Value: accessed-variable=VeAATR_b_SCP_InletTemp_FA.Value
              OUT_VeAATR_T_SCP_DCPstvTemp_Value: accessed-variable=VeAATR_T_SCP_DCPstvTemp.Value
              OUT_VeAATR_b_SCP_DCPstvTemp_FA_Value: accessed-variable=VeAATR_b_SCP_DCPstvTemp_FA.Value
              OUT_VeAATR_T_SCP_DCNegtvTemp_Value: accessed-variable=VeAATR_T_SCP_DCNegtvTemp.Value
              OUT_VeAATR_b_SCP_DCNegtvTemp_FA_Value: accessed-variable=VeAATR_b_SCP_DCNegtvTemp_FA.Value
              OUT_VeAATR_U_CBC_AmbAirVoltRaw_Value: accessed-variable=VeAATR_U_CBC_AmbAirVoltRaw.Value
              OUT_VeAATR_e_EstAmbAirTempSource_Value: accessed-variable=VeAATR_e_EstAmbAirTempSource.Value
              OUT_VeAATR_T_SCP_AmbientTemp_Value: accessed-variable=VeAATR_T_SCP_AmbientTemp.Value
              OUT_VeAATR_T_CBC_AmbAirTempRaw_Value: accessed-variable=VeAATR_T_CBC_AmbAirTempRaw.Value
              OUT_VeAATR_b_IUMPR_CBCAmbAirTemp_Perf_Value: accessed-variable=VeAATR_b_IUMPR_CBCAmbAirTemp_Perf.Value, variation-point={short-label=vpOUT_VeAATR_b_IUMPR_CBCAmbAirTemp_Perf_Value, sw-syscond=1}
              OUT_VeAATR_b_IUMPR_SCP_AmbTemp_Perf_Value: accessed-variable=VeAATR_b_IUMPR_SCP_AmbTemp_Perf.Value, variation-point={short-label=vpOUT_VeAATR_b_IUMPR_SCP_AmbTemp_Perf_Value, sw-syscond=1}
              OUT_VeAATR_b_IUMPR_SCP_InletTemp_Perf_Value: accessed-variable=VeAATR_b_IUMPR_SCP_InletTemp_Perf.Value, variation-point={short-label=vpOUT_VeAATR_b_IUMPR_SCP_InletTemp_Perf_Value, sw-syscond=1}
              OUT_VeAATR_T_SCP_InletTemp_Value: accessed-variable=VeAATR_T_SCP_InletTemp.Value
              OUT_VeAATR_e_FaultSts_AAT_SnsrCktHi_Value: accessed-variable=VeAATR_e_FaultSts_AAT_SnsrCktHi.Value
              OUT_VeAATR_e_FaultSts_AAT_SnsrCktLo_Value: accessed-variable=VeAATR_e_FaultSts_AAT_SnsrCktLo.Value
              OUT_VeAATR_e_FaultSts_BatChaCouTemSenACirHig_Value: accessed-variable=VeAATR_e_FaultSts_BatChaCouTemSenACirHig.Value
              OUT_VeAATR_e_FaultSts_BatChaCouTemSenACirLow_Value: accessed-variable=VeAATR_e_FaultSts_BatChaCouTemSenACirLow.Value
              OUT_VeAATR_e_FaultSts_BatChaCouTemSnsrCkt_Value: accessed-variable=VeAATR_e_FaultSts_BatChaCouTemSnsrCkt.Value
              OUT_VeAATR_e_FaultSts_BattChrgCouTempSnsrCCktHi_Value: accessed-variable=VeAATR_e_FaultSts_BattChrgCouTempSnsrCCktHi.Value
              OUT_VeAATR_e_FaultSts_BattChrgCouTempSnsrCCktLo_Value: accessed-variable=VeAATR_e_FaultSts_BattChrgCouTempSnsrCCktLo.Value
              OUT_VeAATR_e_FaultSts_BattChrgCouTempSnsrCCkt_Value: accessed-variable=VeAATR_e_FaultSts_BattChrgCouTempSnsrCCkt.Value
              OUT_VeAATR_e_FaultSts_BattChrgCouTempSnsrBCktHi_Value: accessed-variable=VeAATR_e_FaultSts_BattChrgCouTempSnsrBCktHi.Value
              OUT_VeAATR_e_FaultSts_BattChrgCouTempSnsrBCktLo_Value: accessed-variable=VeAATR_e_FaultSts_BattChrgCouTempSnsrBCktLo.Value
              OUT_VeAATR_e_FaultSts_BattChrgCouTempSnsrBCkt_Value: accessed-variable=VeAATR_e_FaultSts_BattChrgCouTempSnsrBCkt.Value
              OUT_VeAATR_e_FaultSts_AAT_SnsrPerf_Value: accessed-variable=VeAATR_e_FaultSts_AAT_SnsrPerf.Value
              OUT_VeAATR_e_FaultSts_BatChaCouTemSenACirRan_Value: accessed-variable=VeAATR_e_FaultSts_BatChaCouTemSenACirRan.Value
              OUT_VeAATR_e_FaultSts_BattChrgCouTempSnsrCCktPerf_Value: accessed-variable=VeAATR_e_FaultSts_BattChrgCouTempSnsrCCktPerf.Value
              OUT_VeAATR_e_FaultSts_BattChrgCouTempSnsrBCktPerf_Value: accessed-variable=VeAATR_e_FaultSts_BattChrgCouTempSnsrBCktPerf.Value
          written-local-variables:
            18 x access:
              WV_AmbAirTempFA_Saved_write_IRV: accessed-variable=AmbAirTempFA_Saved_write_IRV, variation-point={short-label=vpWV_AmbAirTempFA_Saved_write_IRV, sw-syscond=1}
              WV_AmbAirTemp_Saved_write_IRV: accessed-variable=AmbAirTemp_Saved_write_IRV, variation-point={short-label=vpWV_AmbAirTemp_Saved_write_IRV, sw-syscond=1}
              WV_CBC_AmbAirTempSrc_Init_write_IRV: accessed-variable=CBC_AmbAirTempSrc_Init_write_IRV
              WV_CBC_AmbAirTemp_InitFA_write_IRV: accessed-variable=CBC_AmbAirTemp_InitFA_write_IRV
              WV_CBC_AmbAirTemp_Init_write_IRV: accessed-variable=CBC_AmbAirTemp_Init_write_IRV
              WV_ECM_AmbAirTemp_InitFA_write_IRV: accessed-variable=ECM_AmbAirTemp_InitFA_write_IRV
              WV_ECM_AmbAirTemp_Init_write_IRV: accessed-variable=ECM_AmbAirTemp_Init_write_IRV
              WV_SCP_AmbientTempFA_Init_write_IRV: accessed-variable=SCP_AmbientTempFA_Init_write_IRV, variation-point={short-label=vpWV_SCP_AmbientTempFA_Init_write_IRV, sw-syscond=1}
              WV_SCP_AmbientTemp_Init_write_IRV: accessed-variable=SCP_AmbientTemp_Init_write_IRV, variation-point={short-label=vpWV_SCP_AmbientTemp_Init_write_IRV, sw-syscond=1}
              WV_SCP_DCNegtvTempFA_Init_write_IRV: accessed-variable=SCP_DCNegtvTempFA_Init_write_IRV, variation-point={short-label=vpWV_SCP_DCNegtvTempFA_Init_write_IRV, sw-syscond=1}
              WV_SCP_DCNegtvTempSNA_Init_write_IRV: accessed-variable=SCP_DCNegtvTempSNA_Init_write_IRV, variation-point={short-label=vpWV_SCP_DCNegtvTempSNA_Init_write_IRV, sw-syscond=1}
              WV_SCP_DCNegtvTemp_Init_write_IRV: accessed-variable=SCP_DCNegtvTemp_Init_write_IRV, variation-point={short-label=vpWV_SCP_DCNegtvTemp_Init_write_IRV, sw-syscond=1}
              WV_SCP_DCPstvTempFA_Init_write_IRV: accessed-variable=SCP_DCPstvTempFA_Init_write_IRV, variation-point={short-label=vpWV_SCP_DCPstvTempFA_Init_write_IRV, sw-syscond=1}
              WV_SCP_DCPstvTempSNA_Init_write_IRV: accessed-variable=SCP_DCPstvTempSNA_Init_write_IRV, variation-point={short-label=vpWV_SCP_DCPstvTempSNA_Init_write_IRV, sw-syscond=1}
              WV_SCP_DCPstvTemp_Init_write_IRV: accessed-variable=SCP_DCPstvTemp_Init_write_IRV, variation-point={short-label=vpWV_SCP_DCPstvTemp_Init_write_IRV, sw-syscond=1}
              WV_SCP_InletTempSnsrFA_Init_write_IRV: accessed-variable=SCP_InletTempSnsrFA_Init_write_IRV, variation-point={short-label=vpWV_SCP_InletTempSnsrFA_Init_write_IRV, sw-syscond=1}
              WV_SCP_InletTempSnsrSNA_Init_write_IRV: accessed-variable=SCP_InletTempSnsrSNA_Init_write_IRV, variation-point={short-label=vpWV_SCP_InletTempSnsrSNA_Init_write_IRV, sw-syscond=1}
              WV_SCP_InletTempSnsr_Init_write_IRV: accessed-variable=SCP_InletTempSnsr_Init_write_IRV, variation-point={short-label=vpWV_SCP_InletTempSnsr_Init_write_IRV, sw-syscond=1}
        AATR_MedTEH
          data-receive-point-by-arguments:
            61 x access:
              IN_VeCSVR_v_VehSpd_Value: accessed-variable=VeCSVR_v_VehSpd.Value, variation-point={short-label=vpIN_VeCSVR_v_VehSpd_Value, sw-syscond=1}
              IN_VeDFIR_b_DsblDiagFailSafe_Value: accessed-variable=VeDFIR_b_DsblDiagFailSafe.Value, variation-point={short-label=vpIN_VeDFIR_b_DsblDiagFailSafe_Value, sw-syscond=1}
              IN_VeDFIR_b_IsDiagGlobalConditionsValid_Value: accessed-variable=VeDFIR_b_IsDiagGlobalConditionsValid.Value, variation-point={short-label=vpIN_VeDFIR_b_IsDiagGlobalConditionsValid_Value, sw-syscond=1}
              IN_VeDFIR_b_PostCodeClrDiagDsbl_Value: accessed-variable=VeDFIR_b_PostCodeClrDiagDsbl.Value, variation-point={short-label=vpIN_VeDFIR_b_PostCodeClrDiagDsbl_Value, sw-syscond=1}
              IN_VeDMAB_y_StatusByte_AAT_SnsrCktHi_Value: accessed-variable=VeDMAB_y_StatusByte_AAT_SnsrCktHi.Value
              IN_VeDMAB_y_StatusByte_AAT_SnsrCktLo_Value: accessed-variable=VeDMAB_y_StatusByte_AAT_SnsrCktLo.Value
              IN_VeDMAB_y_StatusByte_AAT_SnsrCkt_B_Hi_Value: accessed-variable=VeDMAB_y_StatusByte_AAT_SnsrCkt_B_Hi.Value
              IN_VeDMAB_y_StatusByte_AAT_SnsrCkt_B_Lo_Value: accessed-variable=VeDMAB_y_StatusByte_AAT_SnsrCkt_B_Lo.Value
              IN_VeDMAB_y_StatusByte_AAT_SnsrCkt_B_Perf_Value: accessed-variable=VeDMAB_y_StatusByte_AAT_SnsrCkt_B_Perf.Value
              IN_VeDMAB_y_StatusByte_AAT_SnsrPerf_Value: accessed-variable=VeDMAB_y_StatusByte_AAT_SnsrPerf.Value
              IN_VeDMAB_y_StatusByte_BatChaCouTemSenACirHig_Value: accessed-variable=VeDMAB_y_StatusByte_BatChaCouTemSenACirHig.Value
              IN_VeDMAB_y_StatusByte_BatChaCouTemSenACirLow_Value: accessed-variable=VeDMAB_y_StatusByte_BatChaCouTemSenACirLow.Value
              IN_VeDMAB_y_StatusByte_BatChaCouTemSenACirRan_Value: accessed-variable=VeDMAB_y_StatusByte_BatChaCouTemSenACirRan.Value
              IN_VeDMAB_y_StatusByte_BatChaCouTemSnsrCkt_Value: accessed-variable=VeDMAB_y_StatusByte_BatChaCouTemSnsrCkt.Value
              IN_VeDMAB_y_StatusByte_BattChrgCouTempSnsrBCkt_Value: accessed-variable=VeDMAB_y_StatusByte_BattChrgCouTempSnsrBCkt.Value
              IN_VeDMAB_y_StatusByte_BattChrgCouTempSnsrBCktHi_Value: accessed-variable=VeDMAB_y_StatusByte_BattChrgCouTempSnsrBCktHi.Value
              IN_VeDMAB_y_StatusByte_BattChrgCouTempSnsrBCktLo_Value: accessed-variable=VeDMAB_y_StatusByte_BattChrgCouTempSnsrBCktLo.Value
              IN_VeDMAB_y_StatusByte_BattChrgCouTempSnsrBCktPerf_Value: accessed-variable=VeDMAB_y_StatusByte_BattChrgCouTempSnsrBCktPerf.Value
              IN_VeDMAB_y_StatusByte_BattChrgCouTempSnsrCCkt_Value: accessed-variable=VeDMAB_y_StatusByte_BattChrgCouTempSnsrCCkt.Value
              IN_VeDMAB_y_StatusByte_BattChrgCouTempSnsrCCktHi_Value: accessed-variable=VeDMAB_y_StatusByte_BattChrgCouTempSnsrCCktHi.Value
              IN_VeDMAB_y_StatusByte_BattChrgCouTempSnsrCCktLo_Value: accessed-variable=VeDMAB_y_StatusByte_BattChrgCouTempSnsrCCktLo.Value
              IN_VeDMAB_y_StatusByte_BattChrgCouTempSnsrCCktPerf_Value: accessed-variable=VeDMAB_y_StatusByte_BattChrgCouTempSnsrCCktPerf.Value
              IN_VeDMAB_y_StatusByte_CT_SnsrCktHi_Value: accessed-variable=VeDMAB_y_StatusByte_CT_SnsrCktHi.Value
              IN_VeDMAB_y_StatusByte_CT_SnsrCktLo_Value: accessed-variable=VeDMAB_y_StatusByte_CT_SnsrCktLo.Value
              IN_VeDMAB_y_StatusByte_CT_SnsrPerf_Value: accessed-variable=VeDMAB_y_StatusByte_CT_SnsrPerf.Value
              IN_VeDMAB_y_StatusByte_CommBusOff_Value: accessed-variable=VeDMAB_y_StatusByte_CommBusOff.Value
              IN_VeDMAB_y_StatusByte_HiSpdCANCommBus_Value: accessed-variable=VeDMAB_y_StatusByte_HiSpdCANCommBus.Value
              IN_VeDMAB_y_StatusByte_HiSpdFD_CAN3CommBus_Value: accessed-variable=VeDMAB_y_StatusByte_HiSpdFD_CAN3CommBus.Value
              IN_VeDMAB_y_StatusByte_HiSpdFD_CAN3CommBusPerf_Value: accessed-variable=VeDMAB_y_StatusByte_HiSpdFD_CAN3CommBusPerf.Value
              IN_VeDMAB_y_StatusByte_InvData_BCM_Value: accessed-variable=VeDMAB_y_StatusByte_InvData_BCM.Value
              IN_VeDMAB_y_StatusByte_InvData_CPIMGen2_Value: accessed-variable=VeDMAB_y_StatusByte_InvData_CPIMGen2.Value
              IN_VeDMAB_y_StatusByte_LIN{1..3}_BusOff_Value: accessed-variable=VeDMAB_y_StatusByte_LIN{1..3}_BusOff.Value
              IN_VeDMAB_y_StatusByte_LostCommBCM_Value: accessed-variable=VeDMAB_y_StatusByte_LostCommBCM.Value
              IN_VeDMAB_y_StatusByte_LostCommCPIM_Value: accessed-variable=VeDMAB_y_StatusByte_LostCommCPIM.Value
              IN_VeDMAB_y_StatusByte_LostCommECM_PCM_A_Value: accessed-variable=VeDMAB_y_StatusByte_LostCommECM_PCM_A.Value
              IN_VeDMAB_y_StatusByte_LostComm_CANC2_BCM_Value: accessed-variable=VeDMAB_y_StatusByte_LostComm_CANC2_BCM.Value
              IN_VeDMAB_y_StatusByte_MtrElect_CT_SnsrCktHi_Value: accessed-variable=VeDMAB_y_StatusByte_MtrElect_CT_SnsrCktHi.Value
              IN_VeDMAB_y_StatusByte_MtrElect_CT_SnsrCktLo_Value: accessed-variable=VeDMAB_y_StatusByte_MtrElect_CT_SnsrCktLo.Value
              IN_VeDMAB_y_StatusByte_MtrElect_CT_SnsrPerf_Value: accessed-variable=VeDMAB_y_StatusByte_MtrElect_CT_SnsrPerf.Value
              IN_VeDMAB_y_StatusByte_MtrElect_CooPumBOvrSpd_Value: accessed-variable=VeDMAB_y_StatusByte_MtrElect_CooPumBOvrSpd.Value
              IN_VeDMAB_y_StatusByte_MtrElect_CoolPmpATempSnsrPerf_Value: accessed-variable=VeDMAB_y_StatusByte_MtrElect_CoolPmpATempSnsrPerf.Value
              IN_VeDMAB_y_StatusByte_MtrElect_CoolPumAOvrSpd_Value: accessed-variable=VeDMAB_y_StatusByte_MtrElect_CoolPumAOvrSpd.Value
              IN_VeDMAB_y_StatusByte_MtrElect_CoolPumBCtrlPerf_Value: accessed-variable=VeDMAB_y_StatusByte_MtrElect_CoolPumBCtrlPerf.Value
              IN_VeDMAB_y_StatusByte_PwrElecPmpPerf_Value: accessed-variable=VeDMAB_y_StatusByte_PwrElecPmpPerf.Value
              IN_VeENGR_T_InductionAirTemp_Value: accessed-variable=VeENGR_T_InductionAirTemp.Value, variation-point={short-label=vpIN_VeENGR_T_InductionAirTemp_Value, sw-syscond=1}
              IN_VeENGR_b_IAT_SnsrFA_Value: accessed-variable=VeENGR_b_IAT_SnsrFA.Value, variation-point={short-label=vpIN_VeENGR_b_IAT_SnsrFA_Value, sw-syscond=1}
              IN_VeESPR_e_EngineSpeedStatus_Value: accessed-variable=VeESPR_e_EngineSpeedStatus.Value, variation-point={short-label=vpIN_VeESPR_e_EngineSpeedStatus_Value, sw-syscond=1}
              IN_VeESPR_n_EngineSpeed_Value: accessed-variable=VeESPR_n_EngineSpeed.Value, variation-point={short-label=vpIN_VeESPR_n_EngineSpeed_Value, sw-syscond=1}
              IN_VeOBCR_e_ChargingLevel_Value: accessed-variable=VeOBCR_e_ChargingLevel.Value, variation-point={short-label=vpIN_VeOBCR_e_ChargingLevel_Value, sw-syscond=1}
              IN_VeOBCR_e_ChargingSystemSts_Value: accessed-variable=VeOBCR_e_ChargingSystemSts.Value, variation-point={short-label=vpIN_VeOBCR_e_ChargingSystemSts_Value, sw-syscond=1}
              IN_VePLTR_b_HCPOffTimeFA_Value: accessed-variable=VePLTR_b_HCPOffTimeFA.Value, variation-point={short-label=vpIN_VePLTR_b_HCPOffTimeFA_Value, sw-syscond=1}
              IN_VePLTR_t_HCPOffTime_Value: accessed-variable=VePLTR_t_HCPOffTime.Value, variation-point={short-label=vpIN_VePLTR_t_HCPOffTime_Value, sw-syscond=1}
              IN_VePMDR_b_RunCrankActive_Value: accessed-variable=VePMDR_b_RunCrankActive.Value, variation-point={short-label=vpIN_VePMDR_b_RunCrankActive_Value, sw-syscond=1}
              IN_VePMIR_T_LTPsvPumpTemp_Value: accessed-variable=VePMIR_T_LTPsvPumpTemp.Value, variation-point={short-label=vpIN_VePMIR_T_LTPsvPumpTemp_Value, sw-syscond=1}
              IN_VePMIR_b_LTPsvPumpTemp_FA_Value: accessed-variable=VePMIR_b_LTPsvPumpTemp_FA.Value, variation-point={short-label=vpIN_VePMIR_b_LTPsvPumpTemp_FA_Value, sw-syscond=1}
              IN_VeTMIR_T_OnBrdChrg_ClntTmpIn_Value: accessed-variable=VeTMIR_T_OnBrdChrg_ClntTmpIn.Value, variation-point={short-label=vpIN_VeTMIR_T_OnBrdChrg_ClntTmpIn_Value, sw-syscond=1}
              IN_VeTMIR_T_PsvPmpClnt_TmpIn_Value: accessed-variable=VeTMIR_T_PsvPmpClnt_TmpIn.Value, variation-point={short-label=vpIN_VeTMIR_T_PsvPmpClnt_TmpIn_Value, sw-syscond=1}
              IN_VeTMIR_b_OnBrdChrg_ClntTmpIn_FA_Value: accessed-variable=VeTMIR_b_OnBrdChrg_ClntTmpIn_FA.Value, variation-point={short-label=vpIN_VeTMIR_b_OnBrdChrg_ClntTmpIn_FA_Value, sw-syscond=1}
              IN_VeTMIR_b_PsvPmpClnt_TmpIn_FA_Value: accessed-variable=VeTMIR_b_PsvPmpClnt_TmpIn_FA.Value, variation-point={short-label=vpIN_VeTMIR_b_PsvPmpClnt_TmpIn_FA_Value, sw-syscond=1}
          data-send-points:
            30 x access:
              OUT_VeAATR_T_EstAmbAirTemp_Value: accessed-variable=VeAATR_T_EstAmbAirTemp.Value
              OUT_VeAATR_b_EstAmbAirTempFA_Value: accessed-variable=VeAATR_b_EstAmbAirTempFA.Value
              OUT_VeAATR_b_SCP_InletTemp_FA_Value: accessed-variable=VeAATR_b_SCP_InletTemp_FA.Value
              OUT_VeAATR_T_SCP_DCPstvTemp_Value: accessed-variable=VeAATR_T_SCP_DCPstvTemp.Value
              OUT_VeAATR_b_SCP_DCPstvTemp_FA_Value: accessed-variable=VeAATR_b_SCP_DCPstvTemp_FA.Value
              OUT_VeAATR_T_SCP_DCNegtvTemp_Value: accessed-variable=VeAATR_T_SCP_DCNegtvTemp.Value
              OUT_VeAATR_b_SCP_DCNegtvTemp_FA_Value: accessed-variable=VeAATR_b_SCP_DCNegtvTemp_FA.Value
              OUT_VeAATR_U_CBC_AmbAirVoltRaw_Value: accessed-variable=VeAATR_U_CBC_AmbAirVoltRaw.Value
              OUT_VeAATR_e_EstAmbAirTempSource_Value: accessed-variable=VeAATR_e_EstAmbAirTempSource.Value
              OUT_VeAATR_T_SCP_AmbientTemp_Value: accessed-variable=VeAATR_T_SCP_AmbientTemp.Value
              OUT_VeAATR_T_CBC_AmbAirTempRaw_Value: accessed-variable=VeAATR_T_CBC_AmbAirTempRaw.Value
              OUT_VeAATR_b_IUMPR_CBCAmbAirTemp_Perf_Value: accessed-variable=VeAATR_b_IUMPR_CBCAmbAirTemp_Perf.Value, variation-point={short-label=vpOUT_VeAATR_b_IUMPR_CBCAmbAirTemp_Perf_Value, sw-syscond=1}
              OUT_VeAATR_b_IUMPR_SCP_AmbTemp_Perf_Value: accessed-variable=VeAATR_b_IUMPR_SCP_AmbTemp_Perf.Value, variation-point={short-label=vpOUT_VeAATR_b_IUMPR_SCP_AmbTemp_Perf_Value, sw-syscond=1}
              OUT_VeAATR_b_IUMPR_SCP_InletTemp_Perf_Value: accessed-variable=VeAATR_b_IUMPR_SCP_InletTemp_Perf.Value, variation-point={short-label=vpOUT_VeAATR_b_IUMPR_SCP_InletTemp_Perf_Value, sw-syscond=1}
              OUT_VeAATR_T_SCP_InletTemp_Value: accessed-variable=VeAATR_T_SCP_InletTemp.Value
              OUT_VeAATR_e_FaultSts_AAT_SnsrCktHi_Value: accessed-variable=VeAATR_e_FaultSts_AAT_SnsrCktHi.Value
              OUT_VeAATR_e_FaultSts_AAT_SnsrCktLo_Value: accessed-variable=VeAATR_e_FaultSts_AAT_SnsrCktLo.Value
              OUT_VeAATR_e_FaultSts_BatChaCouTemSenACirHig_Value: accessed-variable=VeAATR_e_FaultSts_BatChaCouTemSenACirHig.Value
              OUT_VeAATR_e_FaultSts_BatChaCouTemSenACirLow_Value: accessed-variable=VeAATR_e_FaultSts_BatChaCouTemSenACirLow.Value
              OUT_VeAATR_e_FaultSts_BatChaCouTemSnsrCkt_Value: accessed-variable=VeAATR_e_FaultSts_BatChaCouTemSnsrCkt.Value
              OUT_VeAATR_e_FaultSts_BattChrgCouTempSnsrCCktHi_Value: accessed-variable=VeAATR_e_FaultSts_BattChrgCouTempSnsrCCktHi.Value
              OUT_VeAATR_e_FaultSts_BattChrgCouTempSnsrCCktLo_Value: accessed-variable=VeAATR_e_FaultSts_BattChrgCouTempSnsrCCktLo.Value
              OUT_VeAATR_e_FaultSts_BattChrgCouTempSnsrCCkt_Value: accessed-variable=VeAATR_e_FaultSts_BattChrgCouTempSnsrCCkt.Value
              OUT_VeAATR_e_FaultSts_BattChrgCouTempSnsrBCktHi_Value: accessed-variable=VeAATR_e_FaultSts_BattChrgCouTempSnsrBCktHi.Value
              OUT_VeAATR_e_FaultSts_BattChrgCouTempSnsrBCktLo_Value: accessed-variable=VeAATR_e_FaultSts_BattChrgCouTempSnsrBCktLo.Value
              OUT_VeAATR_e_FaultSts_BattChrgCouTempSnsrBCkt_Value: accessed-variable=VeAATR_e_FaultSts_BattChrgCouTempSnsrBCkt.Value
              OUT_VeAATR_e_FaultSts_AAT_SnsrPerf_Value: accessed-variable=VeAATR_e_FaultSts_AAT_SnsrPerf.Value
              OUT_VeAATR_e_FaultSts_BatChaCouTemSenACirRan_Value: accessed-variable=VeAATR_e_FaultSts_BatChaCouTemSenACirRan.Value
              OUT_VeAATR_e_FaultSts_BattChrgCouTempSnsrCCktPerf_Value: accessed-variable=VeAATR_e_FaultSts_BattChrgCouTempSnsrCCktPerf.Value
              OUT_VeAATR_e_FaultSts_BattChrgCouTempSnsrBCktPerf_Value: accessed-variable=VeAATR_e_FaultSts_BattChrgCouTempSnsrBCktPerf.Value
          read-local-variables:
            17 x access:
              RV_AmbAirTempFA_Saved_write_IRV: accessed-variable=AmbAirTempFA_Saved_write_IRV, variation-point={short-label=vpRV_AmbAirTempFA_Saved_write_IRV, sw-syscond=1}
              RV_AmbAirTemp_Saved_write_IRV: accessed-variable=AmbAirTemp_Saved_write_IRV, variation-point={short-label=vpRV_AmbAirTemp_Saved_write_IRV, sw-syscond=1}
              RV_CBC_AmbAirTemp_InitFA_write_IRV: accessed-variable=CBC_AmbAirTemp_InitFA_write_IRV, variation-point={short-label=vpRV_CBC_AmbAirTemp_InitFA_write_IRV, sw-syscond=1}
              RV_CBC_AmbAirTemp_Init_write_IRV: accessed-variable=CBC_AmbAirTemp_Init_write_IRV
              RV_ECM_AmbAirTemp_InitFA_write_IRV: accessed-variable=ECM_AmbAirTemp_InitFA_write_IRV
              RV_ECM_AmbAirTemp_Init_write_IRV: accessed-variable=ECM_AmbAirTemp_Init_write_IRV
              RV_SCP_AmbientTempFA_Init_write_IRV: accessed-variable=SCP_AmbientTempFA_Init_write_IRV, variation-point={short-label=vpRV_SCP_AmbientTempFA_Init_write_IRV, sw-syscond=1}
              RV_SCP_AmbientTemp_Init_write_IRV: accessed-variable=SCP_AmbientTemp_Init_write_IRV, variation-point={short-label=vpRV_SCP_AmbientTemp_Init_write_IRV, sw-syscond=1}
              RV_SCP_DCNegtvTempFA_Init_write_IRV: accessed-variable=SCP_DCNegtvTempFA_Init_write_IRV, variation-point={short-label=vpRV_SCP_DCNegtvTempFA_Init_write_IRV, sw-syscond=1}
              RV_SCP_DCNegtvTempSNA_Init_write_IRV: accessed-variable=SCP_DCNegtvTempSNA_Init_write_IRV, variation-point={short-label=vpRV_SCP_DCNegtvTempSNA_Init_write_IRV, sw-syscond=1}
              RV_SCP_DCNegtvTemp_Init_write_IRV: accessed-variable=SCP_DCNegtvTemp_Init_write_IRV, variation-point={short-label=vpRV_SCP_DCNegtvTemp_Init_write_IRV, sw-syscond=1}
              RV_SCP_DCPstvTempFA_Init_write_IRV: accessed-variable=SCP_DCPstvTempFA_Init_write_IRV, variation-point={short-label=vpRV_SCP_DCPstvTempFA_Init_write_IRV, sw-syscond=1}
              RV_SCP_DCPstvTempSNA_Init_write_IRV: accessed-variable=SCP_DCPstvTempSNA_Init_write_IRV, variation-point={short-label=vpRV_SCP_DCPstvTempSNA_Init_write_IRV, sw-syscond=1}
              RV_SCP_DCPstvTemp_Init_write_IRV: accessed-variable=SCP_DCPstvTemp_Init_write_IRV, variation-point={short-label=vpRV_SCP_DCPstvTemp_Init_write_IRV, sw-syscond=1}
              RV_SCP_InletTempSnsrFA_Init_write_IRV: accessed-variable=SCP_InletTempSnsrFA_Init_write_IRV, variation-point={short-label=vpRV_SCP_InletTempSnsrFA_Init_write_IRV, sw-syscond=1}
              RV_SCP_InletTempSnsrSNA_Init_write_IRV: accessed-variable=SCP_InletTempSnsrSNA_Init_write_IRV, variation-point={short-label=vpRV_SCP_InletTempSnsrSNA_Init_write_IRV, sw-syscond=1}
              RV_SCP_InletTempSnsr_Init_write_IRV: accessed-variable=SCP_InletTempSnsr_Init_write_IRV, variation-point={short-label=vpRV_SCP_InletTempSnsr_Init_write_IRV, sw-syscond=1}
        AATR_PwrOff
          data-send-points:
            18 x access:
              OUT_NeAATR_T_AmbAirTempPred_Prev_NeAATR_T_AmbAirTempPred_Prev: accessed-variable=NeAATR_T_AmbAirTempPred_Prev.NeAATR_T_AmbAirTempPred_Prev
              OUT_NeAATR_b_AmbAirTempPred_PrevFA_NeAATR_b_AmbAirTempPred_PrevFA: accessed-variable=NeAATR_b_AmbAirTempPred_PrevFA.NeAATR_b_AmbAirTempPred_PrevFA
              OUT_NeAATR_Cnt_AmbAirTemp_PerfFlt_MFOP_NeAATR_Cnt_AmbAirTemp_PerfFlt_MFOP: accessed-variable=NeAATR_Cnt_AmbAirTemp_PerfFlt_MFOP.NeAATR_Cnt_AmbAirTemp_PerfFlt_MFOP
              OUT_NeAATR_Cnt_AmbAirVolt_HiFlt_MFOP_NeAATR_Cnt_AmbAirVolt_HiFlt_MFOP: accessed-variable=NeAATR_Cnt_AmbAirVolt_HiFlt_MFOP.NeAATR_Cnt_AmbAirVolt_HiFlt_MFOP
              OUT_NeAATR_Cnt_AmbAirVolt_LoFlt_MFOP_NeAATR_Cnt_AmbAirVolt_LoFlt_MFOP: accessed-variable=NeAATR_Cnt_AmbAirVolt_LoFlt_MFOP.NeAATR_Cnt_AmbAirVolt_LoFlt_MFOP
              OUT_NeAATR_Cnt_DCPstvTemp_HiFlt_MFOP_NeAATR_Cnt_DCPstvTemp_HiFlt_MFOP: accessed-variable=NeAATR_Cnt_DCPstvTemp_HiFlt_MFOP.NeAATR_Cnt_DCPstvTemp_HiFlt_MFOP
              OUT_NeAATR_Cnt_ECM_IntakeTemp_PerfFlt_MFOP_NeAATR_Cnt_ECM_IntakeTemp_PerfFlt_MFOP: accessed-variable=NeAATR_Cnt_ECM_IntakeTemp_PerfFlt_MFOP.NeAATR_Cnt_ECM_IntakeTemp_PerfFlt_MFOP
              OUT_NeAATR_Cnt_SCP_DCNegtvTemp_Flt_MFOP_NeAATR_Cnt_SCP_DCNegtvTemp_Flt_MFOP: accessed-variable=NeAATR_Cnt_SCP_DCNegtvTemp_Flt_MFOP.NeAATR_Cnt_SCP_DCNegtvTemp_Flt_MFOP
              OUT_NeAATR_Cnt_SCP_DCNegtvTemp_HiFlt_MFOP_NeAATR_Cnt_SCP_DCNegtvTemp_HiFlt_MFOP: accessed-variable=NeAATR_Cnt_SCP_DCNegtvTemp_HiFlt_MFOP.NeAATR_Cnt_SCP_DCNegtvTemp_HiFlt_MFOP
              OUT_NeAATR_Cnt_SCP_DCNegtvTemp_LoFlt_MFOP_NeAATR_Cnt_SCP_DCNegtvTemp_LoFlt_MFOP: accessed-variable=NeAATR_Cnt_SCP_DCNegtvTemp_LoFlt_MFOP.NeAATR_Cnt_SCP_DCNegtvTemp_LoFlt_MFOP
              OUT_NeAATR_Cnt_SCP_DCNegtvTemp_PerfFlt_MFOP_NeAATR_Cnt_SCP_DCNegtvTemp_PerfFlt_MFOP: accessed-variable=NeAATR_Cnt_SCP_DCNegtvTemp_PerfFlt_MFOP.NeAATR_Cnt_SCP_DCNegtvTemp_PerfFlt_MFOP
              OUT_NeAATR_Cnt_SCP_DCPstvTemp_Flt_MFOP_NeAATR_Cnt_SCP_DCPstvTemp_Flt_MFOP: accessed-variable=NeAATR_Cnt_SCP_DCPstvTemp_Flt_MFOP.NeAATR_Cnt_SCP_DCPstvTemp_Flt_MFOP
              OUT_NeAATR_Cnt_SCP_DCPstvTemp_LoFlt_MFOP_NeAATR_Cnt_SCP_DCPstvTemp_LoFlt_MFOP: accessed-variable=NeAATR_Cnt_SCP_DCPstvTemp_LoFlt_MFOP.NeAATR_Cnt_SCP_DCPstvTemp_LoFlt_MFOP
              OUT_NeAATR_Cnt_SCP_DCPstvTemp_PerfFlt_MFOP_NeAATR_Cnt_SCP_DCPstvTemp_PerfFlt_MFOP: accessed-variable=NeAATR_Cnt_SCP_DCPstvTemp_PerfFlt_MFOP.NeAATR_Cnt_SCP_DCPstvTemp_PerfFlt_MFOP
              OUT_NeAATR_Cnt_SCP_InletTemp_Flt_MFOP_NeAATR_Cnt_SCP_InletTemp_Flt_MFOP: accessed-variable=NeAATR_Cnt_SCP_InletTemp_Flt_MFOP.NeAATR_Cnt_SCP_InletTemp_Flt_MFOP
              OUT_NeAATR_Cnt_SCP_InletTemp_HiFlt_MFOP_NeAATR_Cnt_SCP_InletTemp_HiFlt_MFOP: accessed-variable=NeAATR_Cnt_SCP_InletTemp_HiFlt_MFOP.NeAATR_Cnt_SCP_InletTemp_HiFlt_MFOP
              OUT_NeAATR_Cnt_SCP_InletTemp_LoFlt_MFOP_NeAATR_Cnt_SCP_InletTemp_LoFlt_MFOP: accessed-variable=NeAATR_Cnt_SCP_InletTemp_LoFlt_MFOP.NeAATR_Cnt_SCP_InletTemp_LoFlt_MFOP
              OUT_NeAATR_Cnt_SCP_InletTemp_PerfFlt_MFOP_NeAATR_Cnt_SCP_InletTemp_PerfFlt_MFOP: accessed-variable=NeAATR_Cnt_SCP_InletTemp_PerfFlt_MFOP.NeAATR_Cnt_SCP_InletTemp_PerfFlt_MFOP
        FsftAATR_T_ECM_AmbientAirTemp
          written-local-variables:
            access WV_ECM_AmbAirTemp_Init_write_IRV: accessed-variable=ECM_AmbAirTemp_Init_write_IRV
            access WV_ECM_AmbAirTemp_InitFA_write_IRV: accessed-variable=ECM_AmbAirTemp_InitFA_write_IRV
        FsftAATR_T_SCP_AmbientTempSnsr: variation-point={short-label=vpFsftAATR_T_SCP_AmbientTempSnsr, sw-syscond=1}
          written-local-variables:
            access WV_SCP_AmbientTemp_Init_write_IRV: accessed-variable=SCP_AmbientTemp_Init_write_IRV, variation-point={short-label=vpWV_SCP_AmbientTemp_Init_write_IRV, sw-syscond=1}
            access WV_SCP_AmbientTempFA_Init_write_IRV: accessed-variable=SCP_AmbientTempFA_Init_write_IRV, variation-point={short-label=vpWV_SCP_AmbientTempFA_Init_write_IRV, sw-syscond=1}
        FsftAATR_T_SCP_DCNegtvTmpSnsr: variation-point={short-label=vpFsftAATR_T_SCP_DCNegtvTmpSnsr, sw-syscond=1}
          written-local-variables:
            access WV_SCP_DCNegtvTemp_Init_write_IRV: accessed-variable=SCP_DCNegtvTemp_Init_write_IRV, variation-point={short-label=vpWV_SCP_DCNegtvTemp_Init_write_IRV, sw-syscond=1}
            access WV_SCP_DCNegtvTempFA_Init_write_IRV: accessed-variable=SCP_DCNegtvTempFA_Init_write_IRV, variation-point={short-label=vpWV_SCP_DCNegtvTempFA_Init_write_IRV, sw-syscond=1}
            access WV_SCP_DCNegtvTempSNA_Init_write_IRV: accessed-variable=SCP_DCNegtvTempSNA_Init_write_IRV, variation-point={short-label=vpWV_SCP_DCNegtvTempSNA_Init_write_IRV, sw-syscond=1}
        FsftAATR_T_SCP_DCPstvTmpSnsr: variation-point={short-label=vpFsftAATR_T_SCP_DCPstvTmpSnsr, sw-syscond=1}
          written-local-variables:
            access WV_SCP_DCPstvTemp_Init_write_IRV: accessed-variable=SCP_DCPstvTemp_Init_write_IRV, variation-point={short-label=vpWV_SCP_DCPstvTemp_Init_write_IRV, sw-syscond=1}
            access WV_SCP_DCPstvTempFA_Init_write_IRV: accessed-variable=SCP_DCPstvTempFA_Init_write_IRV, variation-point={short-label=vpWV_SCP_DCPstvTempFA_Init_write_IRV, sw-syscond=1}
            access WV_SCP_DCPstvTempSNA_Init_write_IRV: accessed-variable=SCP_DCPstvTempSNA_Init_write_IRV, variation-point={short-label=vpWV_SCP_DCPstvTempSNA_Init_write_IRV, sw-syscond=1}
        FsftAATR_T_SCP_InletTempSnsr: variation-point={short-label=vpFsftAATR_T_SCP_InletTempSnsr, sw-syscond=1}
          written-local-variables:
            access WV_SCP_InletTempSnsr_Init_write_IRV: accessed-variable=SCP_InletTempSnsr_Init_write_IRV, variation-point={short-label=vpWV_SCP_InletTempSnsr_Init_write_IRV, sw-syscond=1}
            access WV_SCP_InletTempSnsrFA_Init_write_IRV: accessed-variable=SCP_InletTempSnsrFA_Init_write_IRV, variation-point={short-label=vpWV_SCP_InletTempSnsrFA_Init_write_IRV, sw-syscond=1}
            access WV_SCP_InletTempSnsrSNA_Init_write_IRV: accessed-variable=SCP_InletTempSnsrSNA_Init_write_IRV, variation-point={short-label=vpWV_SCP_InletTempSnsrSNA_Init_write_IRV, sw-syscond=1}
        FsftAATR_U_CBC_AmbientAirVolt
          written-local-variables:
            access WV_CBC_AmbAirTemp_Init_write_IRV: accessed-variable=CBC_AmbAirTemp_Init_write_IRV
            access WV_CBC_AmbAirTemp_InitFA_write_IRV: accessed-variable=CBC_AmbAirTemp_InitFA_write_IRV, variation-point={short-label=vpWV_CBC_AmbAirTemp_InitFA_write_IRV, sw-syscond=1}
            access WV_CBC_AmbAirTempSrc_Init_write_IRV: accessed-variable=CBC_AmbAirTempSrc_Init_write_IRV, variation-point={short-label=vpWV_CBC_AmbAirTempSrc_Init_write_IRV, sw-syscond=1}
        PokeAATR_T_ECM_AmbientAirTemp
          written-local-variables:
            access WV_ECM_AmbAirTemp_Init_write_IRV: accessed-variable=ECM_AmbAirTemp_Init_write_IRV
            access WV_ECM_AmbAirTemp_InitFA_write_IRV: accessed-variable=ECM_AmbAirTemp_InitFA_write_IRV
        PokeAATR_T_SCP_AmbientTempSnsr: variation-point={short-label=vpPokeAATR_T_SCP_AmbientTempSnsr, sw-syscond=1}
          written-local-variables:
            access WV_SCP_AmbientTemp_Init_write_IRV: accessed-variable=SCP_AmbientTemp_Init_write_IRV, variation-point={short-label=vpWV_SCP_AmbientTemp_Init_write_IRV, sw-syscond=1}
            access WV_SCP_AmbientTempFA_Init_write_IRV: accessed-variable=SCP_AmbientTempFA_Init_write_IRV, variation-point={short-label=vpWV_SCP_AmbientTempFA_Init_write_IRV, sw-syscond=1}
        PokeAATR_T_SCP_DCNegtvTmpSnsr: variation-point={short-label=vpPokeAATR_T_SCP_DCNegtvTmpSnsr, sw-syscond=1}
          written-local-variables:
            access WV_SCP_DCNegtvTemp_Init_write_IRV: accessed-variable=SCP_DCNegtvTemp_Init_write_IRV, variation-point={short-label=vpWV_SCP_DCNegtvTemp_Init_write_IRV, sw-syscond=1}
            access WV_SCP_DCNegtvTempFA_Init_write_IRV: accessed-variable=SCP_DCNegtvTempFA_Init_write_IRV, variation-point={short-label=vpWV_SCP_DCNegtvTempFA_Init_write_IRV, sw-syscond=1}
            access WV_SCP_DCNegtvTempSNA_Init_write_IRV: accessed-variable=SCP_DCNegtvTempSNA_Init_write_IRV, variation-point={short-label=vpWV_SCP_DCNegtvTempSNA_Init_write_IRV, sw-syscond=1}
        PokeAATR_T_SCP_DCPstvTmpSnsr: variation-point={short-label=vpPokeAATR_T_SCP_DCPstvTmpSnsr, sw-syscond=1}
          written-local-variables:
            access WV_SCP_DCPstvTemp_Init_write_IRV: accessed-variable=SCP_DCPstvTemp_Init_write_IRV, variation-point={short-label=vpWV_SCP_DCPstvTemp_Init_write_IRV, sw-syscond=1}
            access WV_SCP_DCPstvTempFA_Init_write_IRV: accessed-variable=SCP_DCPstvTempFA_Init_write_IRV, variation-point={short-label=vpWV_SCP_DCPstvTempFA_Init_write_IRV, sw-syscond=1}
            access WV_SCP_DCPstvTempSNA_Init_write_IRV: accessed-variable=SCP_DCPstvTempSNA_Init_write_IRV, variation-point={short-label=vpWV_SCP_DCPstvTempSNA_Init_write_IRV, sw-syscond=1}
        PokeAATR_T_SCP_InletTempSnsr: variation-point={short-label=vpPokeAATR_T_SCP_InletTempSnsr, sw-syscond=1}
          written-local-variables:
            access WV_SCP_InletTempSnsr_Init_write_IRV: accessed-variable=SCP_InletTempSnsr_Init_write_IRV, variation-point={short-label=vpWV_SCP_InletTempSnsr_Init_write_IRV, sw-syscond=1}
            access WV_SCP_InletTempSnsrFA_Init_write_IRV: accessed-variable=SCP_InletTempSnsrFA_Init_write_IRV, variation-point={short-label=vpWV_SCP_InletTempSnsrFA_Init_write_IRV, sw-syscond=1}
            access WV_SCP_InletTempSnsrSNA_Init_write_IRV: accessed-variable=SCP_InletTempSnsrSNA_Init_write_IRV, variation-point={short-label=vpWV_SCP_InletTempSnsrSNA_Init_write_IRV, sw-syscond=1}
        PokeAATR_U_CBC_AmbientAirVolt
          written-local-variables:
            access WV_CBC_AmbAirTemp_Init_write_IRV: accessed-variable=CBC_AmbAirTemp_Init_write_IRV
            access WV_CBC_AmbAirTemp_InitFA_write_IRV: accessed-variable=CBC_AmbAirTemp_InitFA_write_IRV, variation-point={short-label=vpWV_CBC_AmbAirTemp_InitFA_write_IRV, sw-syscond=1}
            access WV_CBC_AmbAirTempSrc_Init_write_IRV: accessed-variable=CBC_AmbAirTempSrc_Init_write_IRV, variation-point={short-label=vpWV_CBC_AmbAirTempSrc_Init_write_IRV, sw-syscond=1}
        TmotAATR_U_CBC_AmbientAirVolt
          written-local-variables:
            access WV_CBC_AmbAirTemp_Init_write_IRV: accessed-variable=CBC_AmbAirTemp_Init_write_IRV
            access WV_CBC_AmbAirTemp_InitFA_write_IRV: accessed-variable=CBC_AmbAirTemp_InitFA_write_IRV, variation-point={short-label=vpWV_CBC_AmbAirTemp_InitFA_write_IRV, sw-syscond=1}
            access WV_CBC_AmbAirTempSrc_Init_write_IRV: accessed-variable=CBC_AmbAirTempSrc_Init_write_IRV, variation-point={short-label=vpWV_CBC_AmbAirTempSrc_Init_write_IRV, sw-syscond=1}
      16 x variation point proxy, all with category=CONDITION:
        Variant_AATR_1: condition-access=0
        Variant_AATR_10: condition-access=1
        Variant_AATR_11: condition-access=0
        Variant_AATR_13: condition-access=1
        Variant_AATR_14: condition-access=0
        Variant_AATR_16: condition-access=1
        Variant_AATR_17: condition-access=0
        Variant_AATR_19: condition-access=0
        Variant_AATR_2: condition-access=1
        Variant_AATR_20: condition-access=1
        Variant_AATR_21: condition-access=1
        Variant_AATR_22: condition-access=0
        Variant_AATR_4: condition-access=1
        Variant_AATR_6: condition-access=1
        Variant_AATR_8: condition-access=1
        Variant_AATR_9: condition-access=0
